VERSION ""

NS_ :

BS_:

BU_:

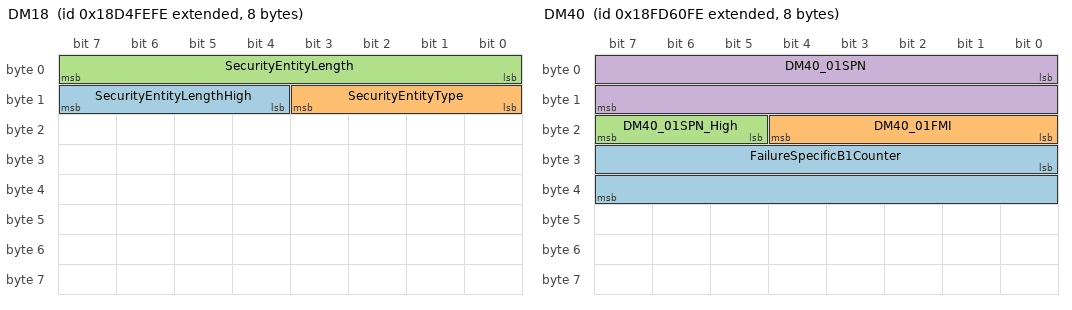
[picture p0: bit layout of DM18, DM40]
BO_ 2564095742 DM18: 8 Vector__XXX
 SG_ SecurityEntityLengthHigh : 12|4@1+ (1,0) [0|255] "Byte" Vector__XXX
 SG_ SecurityEntityType : 8|4@1+ (1,0) [0|15] "" Vector__XXX
 SG_ SecurityEntityLength : 0|8@1+ (1,0) [0|1785] "Byte" Vector__XXX

BO_ 2566742270 DM40: 8 Vector__XXX
 SG_ FailureSpecificB1Counter : 24|16@1+ (0.1,0) [0|6425.5] "hr" Vector__XXX
 SG_ DM40_01FMI : 16|5@1+ (1,0) [0|0] "" Vector__XXX
 SG_ DM40_01SPN_High : 21|3@1+ (65536,0) [0|0] "" Vector__XXX
 SG_ DM40_01SPN : 0|16@1+ (1,0) [0|65536] "" Vector__XXX

BO_ 2566742526 DM39: 8 Vector__XXX
 SG_ SysGreatestB1Counter : 32|16@1+ (0.1,0) [0|6425.5] "hr" Vector__XXX
 SG_ SysCumulativeContinuousMITime : 0|32@1+ (0.05,0) [0|210554060.75] "hr" Vector__XXX

BO_ 2566742782 DM38: 8 Vector__XXX
 SG_ RegulationDescription : 0|8@1+ (1,0) [0|255] "" Vector__XXX

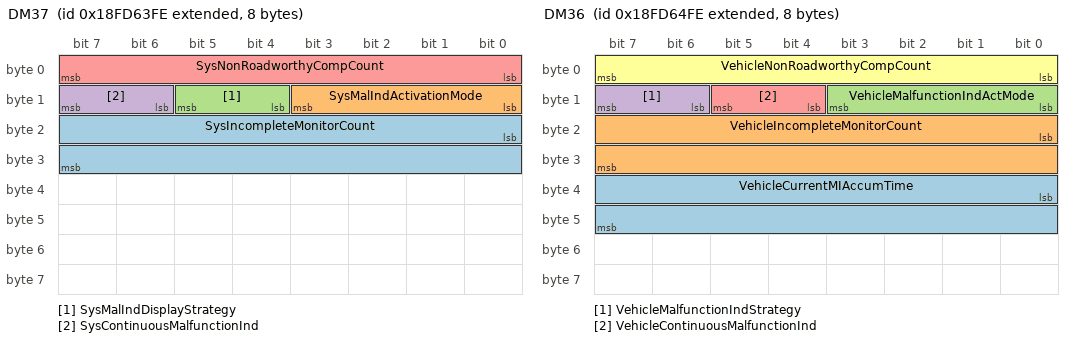
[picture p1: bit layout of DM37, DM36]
BO_ 2566743038 DM37: 8 Vector__XXX
 SG_ SysIncompleteMonitorCount : 16|16@1+ (1,0) [0|64512] "" Vector__XXX
 SG_ SysMalIndActivationMode : 8|4@1+ (1,0) [0|15] "" Vector__XXX
 SG_ SysMalIndDisplayStrategy : 12|2@1+ (1,0) [0|3] "" Vector__XXX
 SG_ SysContinuousMalfunctionInd : 14|2@1+ (1,0) [0|3] "" Vector__XXX
 SG_ SysNonRoadworthyCompCount : 0|8@1+ (1,0) [0|250] "" Vector__XXX

BO_ 2566743294 DM36: 8 Vector__XXX
 SG_ VehicleCurrentMIAccumTime : 32|16@1+ (1,0) [0|64255] "min" Vector__XXX
 SG_ VehicleIncompleteMonitorCount : 16|16@1+ (1,0) [0|64255] "" Vector__XXX
 SG_ VehicleMalfunctionIndActMode : 8|4@1+ (1,0) [0|15] "" Vector__XXX
 SG_ VehicleMalfunctionIndStrategy : 14|2@1+ (1,0) [0|3] "" Vector__XXX
 SG_ VehicleContinuousMalfunctionInd : 12|2@1+ (1,0) [0|3] "" Vector__XXX
 SG_ VehicleNonRoadworthyCompCount : 0|8@1+ (1,0) [0|250] "" Vector__XXX

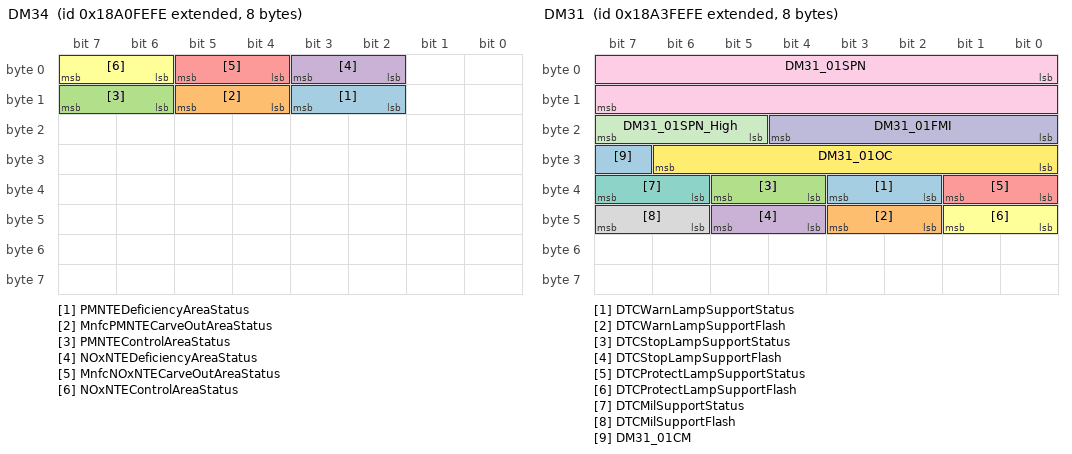
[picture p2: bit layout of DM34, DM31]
BO_ 2560687870 DM34: 8 Vector__XXX
 SG_ PMNTEDeficiencyAreaStatus : 10|2@1+ (1,0) [0|3] "" Vector__XXX
 SG_ MnfcPMNTECarveOutAreaStatus : 12|2@1+ (1,0) [0|3] "" Vector__XXX
 SG_ PMNTEControlAreaStatus : 14|2@1+ (1,0) [0|3] "" Vector__XXX
 SG_ NOxNTEDeficiencyAreaStatus : 2|2@1+ (1,0) [0|3] "" Vector__XXX
 SG_ MnfcNOxNTECarveOutAreaStatus : 4|2@1+ (1,0) [0|3] "" Vector__XXX
 SG_ NOxNTEControlAreaStatus : 6|2@1+ (1,0) [0|3] "" Vector__XXX

BO_ 2292317950 DM33: 9 Vector__XXX
 SG_ AECDEngineHours1Timer2 : 40|32@1+ (1,0) [0|4294967295] "min" Vector__XXX
 SG_ AECDEngineHours1Timer1 : 8|32@1+ (1,0) [0|4294967295] "min" Vector__XXX
 SG_ AECDNumber1 : 0|8@1+ (1,0) [0|250] "" Vector__XXX

BO_ 2560884478 DM31: 8 Vector__XXX
 SG_ DTCWarnLampSupportStatus : 34|2@1+ (1,0) [0|3] "" Vector__XXX
 SG_ DTCWarnLampSupportFlash : 42|2@1+ (1,0) [0|3] "" Vector__XXX
 SG_ DTCStopLampSupportStatus : 36|2@1+ (1,0) [0|3] "" Vector__XXX
 SG_ DTCStopLampSupportFlash : 44|2@1+ (1,0) [0|3] "" Vector__XXX
 SG_ DTCProtectLampSupportStatus : 32|2@1+ (1,0) [0|3] "" Vector__XXX
 SG_ DTCProtectLampSupportFlash : 40|2@1+ (1,0) [0|3] "" Vector__XXX
 SG_ DTCMilSupportStatus : 38|2@1+ (1,0) [0|3] "" Vector__XXX
 SG_ DTCMilSupportFlash : 46|2@1+ (1,0) [0|3] "" Vector__XXX
 SG_ DM31_01SPN : 0|16@1+ (1,0) [0|0] "" Vector__XXX
 SG_ DM31_01FMI : 16|5@1+ (1,0) [0|0] "" Vector__XXX
 SG_ DM31_01SPN_High : 21|3@1+ (65536,0) [0|0] "" Vector__XXX
 SG_ DM31_01OC : 24|7@1+ (1,0) [0|0] "" Vector__XXX
 SG_ DM31_01CM : 31|1@1+ (1,0) [0|0] "" Vector__XXX

BO_ 2560950014 DM30: 12 Vector__XXX
 SG_ TestLimitMinimum : 80|16@1+ (1,0) [0|64255] "" Vector__XXX
 SG_ TestLimitMaximum : 64|16@1+ (1,0) [0|64255] "" Vector__XXX
 SG_ TestValue : 48|16@1+ (1,0) [0|64255] "" Vector__XXX
 SG_ SlotId : 32|16@1+ (1,0) [0|64255] "" Vector__XXX
 SG_ TestIdentifier : 0|8@1+ (1,0) [0|255] "" Vector__XXX
 SG_ DM30_01FMI : 24|5@1+ (1,0) [0|0] "" Vector__XXX
 SG_ DM30_01SPN_High : 29|3@1+ (65536,0) [0|0] "" Vector__XXX
 SG_ DM30_01SPN : 8|16@1+ (1,0) [0|65536] "" Vector__XXX

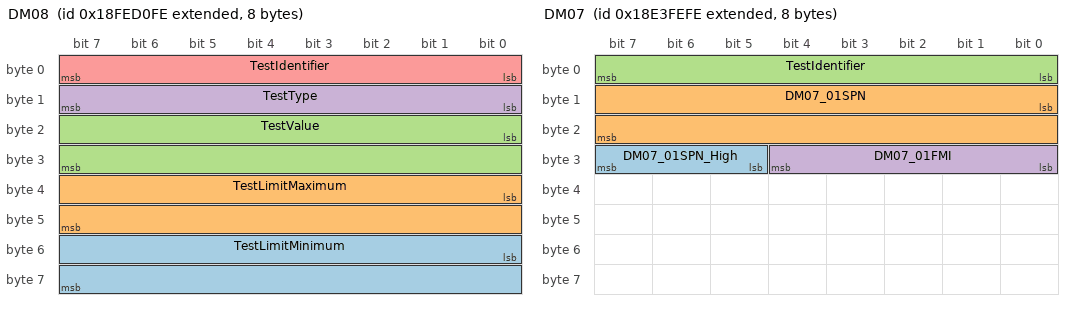
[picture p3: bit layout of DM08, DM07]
BO_ 2566836478 DM08: 8 Vector__XXX
 SG_ TestLimitMinimum : 48|16@1+ (1,0) [0|64255] "" Vector__XXX
 SG_ TestLimitMaximum : 32|16@1+ (1,0) [0|64255] "" Vector__XXX
 SG_ TestValue : 16|16@1+ (1,0) [0|64255] "" Vector__XXX
 SG_ TestType : 8|8@1+ (1,0) [1|64] "" Vector__XXX
 SG_ TestIdentifier : 0|8@1+ (1,0) [1|64] "" Vector__XXX

BO_ 2565078782 DM07: 8 Vector__XXX
 SG_ DM07_01SPN_High : 29|3@1+ (65536,0) [0|0] "" Vector__XXX
 SG_ DM07_01SPN : 8|16@1+ (1,0) [0|65536] "" Vector__XXX
 SG_ TestIdentifier : 0|8@1+ (1,0) [1|64] "" Vector__XXX
 SG_ DM07_01FMI : 24|5@1+ (1,0) [0|0] "" Vector__XXX

BO_ 2566836222 DM06: 78 Vector__XXX
 SG_ FlashRedStopLamp : 12|2@1+ (1,0) [0|3] "" Vector__XXX
 SG_ FlashProtectLamp : 8|2@1+ (1,0) [0|3] "" Vector__XXX
 SG_ FlashMalfuncIndicatorLamp : 14|2@1+ (1,0) [0|3] "" Vector__XXX
 SG_ FlashAmberWarningLamp : 10|2@1+ (1,0) [0|3] "" Vector__XXX
 SG_ MalfunctionIndicatorLampStatus : 6|2@1+ (1,0) [0|3] "" Vector__XXX
 SG_ RedStopLampStatus : 4|2@1+ (1,0) [0|3] "" Vector__XXX
 SG_ AmberWarningLampStatus : 2|2@1+ (1,0) [0|3] "" Vector__XXX
 SG_ ProtectLampStatus : 0|2@1+ (1,0) [0|3] "" Vector__XXX
 SG_ DM06_01OC : 40|7@1+ (1,0) [0|0] "" Vector__XXX
 SG_ DM06_01FMI : 32|5@1+ (1,0) [0|0] "" Vector__XXX
 SG_ DM06_01SPN : 16|16@1+ (1,0) [0|0] "" Vector__XXX
 SG_ DM06_02OC : 72|7@1+ (1,0) [0|0] "" Vector__XXX
 SG_ DM06_02FMI : 64|5@1+ (1,0) [0|0] "" Vector__XXX
 SG_ DM06_02SPN : 48|16@1+ (1,0) [0|0] "" Vector__XXX
 SG_ DM06_03OC : 104|7@1+ (1,0) [0|0] "" Vector__XXX
 SG_ DM06_03FMI : 96|5@1+ (1,0) [0|0] "" Vector__XXX
 SG_ DM06_03SPN : 80|16@1+ (1,0) [0|0] "" Vector__XXX
 SG_ DM06_04OC : 136|7@1+ (1,0) [0|0] "" Vector__XXX
 SG_ DM06_04FMI : 128|5@1+ (1,0) [0|0] "" Vector__XXX
 SG_ DM06_04SPN : 112|16@1+ (1,0) [0|0] "" Vector__XXX
 SG_ DM06_05OC : 168|7@1+ (1,0) [0|0] "" Vector__XXX
 SG_ DM06_05FMI : 160|5@1+ (1,0) [0|0] "" Vector__XXX
 SG_ DM06_05SPN : 144|16@1+ (1,0) [0|0] "" Vector__XXX
 SG_ DM06_06OC : 200|7@1+ (1,0) [0|0] "" Vector__XXX
 SG_ DM06_06FMI : 192|5@1+ (1,0) [0|0] "" Vector__XXX
 SG_ DM06_06SPN : 176|16@1+ (1,0) [0|0] "" Vector__XXX
 SG_ DM06_07OC : 232|7@1+ (1,0) [0|0] "" Vector__XXX
 SG_ DM06_07FMI : 224|5@1+ (1,0) [0|0] "" Vector__XXX
 SG_ DM06_07SPN : 208|16@1+ (1,0) [0|0] "" Vector__XXX
 SG_ DM06_08OC : 264|7@1+ (1,0) [0|0] "" Vector__XXX
 SG_ DM06_08FMI : 256|5@1+ (1,0) [0|0] "" Vector__XXX
 SG_ DM06_08SPN : 240|16@1+ (1,0) [0|0] "" Vector__XXX
 SG_ DM06_09OC : 296|7@1+ (1,0) [0|0] "" Vector__XXX
 SG_ DM06_09FMI : 288|5@1+ (1,0) [0|0] "" Vector__XXX
 SG_ DM06_09SPN : 272|16@1+ (1,0) [0|0] "" Vector__XXX
 SG_ DM06_10OC : 328|7@1+ (1,0) [0|0] "" Vector__XXX
 SG_ DM06_10FMI : 320|5@1+ (1,0) [0|0] "" Vector__XXX
 SG_ DM06_10SPN : 304|16@1+ (1,0) [0|0] "" Vector__XXX
 SG_ DM06_11OC : 360|7@1+ (1,0) [0|0] "" Vector__XXX
 SG_ DM06_11FMI : 352|5@1+ (1,0) [0|0] "" Vector__XXX
 SG_ DM06_11SPN : 336|16@1+ (1,0) [0|0] "" Vector__XXX
 SG_ DM06_12OC : 392|7@1+ (1,0) [0|0] "" Vector__XXX
 SG_ DM06_12FMI : 384|5@1+ (1,0) [0|0] "" Vector__XXX
 SG_ DM06_12SPN : 368|16@1+ (1,0) [0|0] "" Vector__XXX
 SG_ DM06_13OC : 424|7@1+ (1,0) [0|0] "" Vector__XXX
 SG_ DM06_13FMI : 416|5@1+ (1,0) [0|0] "" Vector__XXX
 SG_ DM06_13SPN : 400|16@1+ (1,0) [0|0] "" Vector__XXX
 SG_ DM06_14OC : 456|7@1+ (1,0) [0|0] "" Vector__XXX
 SG_ DM06_14FMI : 448|5@1+ (1,0) [0|0] "" Vector__XXX
 SG_ DM06_14SPN : 432|16@1+ (1,0) [0|0] "" Vector__XXX
 SG_ DM06_15OC : 488|7@1+ (1,0) [0|0] "" Vector__XXX
 SG_ DM06_15FMI : 480|5@1+ (1,0) [0|0] "" Vector__XXX
 SG_ DM06_15SPN : 464|16@1+ (1,0) [0|0] "" Vector__XXX
 SG_ DM06_16OC : 520|7@1+ (1,0) [0|0] "" Vector__XXX
 SG_ DM06_16FMI : 512|5@1+ (1,0) [0|0] "" Vector__XXX
 SG_ DM06_16SPN : 496|16@1+ (1,0) [0|0] "" Vector__XXX
 SG_ DM06_17OC : 552|7@1+ (1,0) [0|0] "" Vector__XXX
 SG_ DM06_17FMI : 544|5@1+ (1,0) [0|0] "" Vector__XXX
 SG_ DM06_17SPN : 528|16@1+ (1,0) [0|0] "" Vector__XXX
 SG_ DM06_18OC : 584|7@1+ (1,0) [0|0] "" Vector__XXX
 SG_ DM06_18FMI : 576|5@1+ (1,0) [0|0] "" Vector__XXX
 SG_ DM06_18SPN : 560|16@1+ (1,0) [0|0] "" Vector__XXX
 SG_ DM06_19OC : 616|7@1+ (1,0) [0|0] "" Vector__XXX
 SG_ DM06_19FMI : 608|5@1+ (1,0) [0|0] "" Vector__XXX
 SG_ DM06_19SPN : 592|16@1+ (1,0) [0|0] "" Vector__XXX
 SG_ DM06_19SPN_High : 613|3@1+ (65536,0) [0|0] "" Vector__XXX
 SG_ DM06_18SPN_High : 581|3@1+ (65536,0) [0|0] "" Vector__XXX
 SG_ DM06_17SPN_High : 549|3@1+ (65536,0) [0|0] "" Vector__XXX
 SG_ DM06_16SPN_High : 517|3@1+ (65536,0) [0|0] "" Vector__XXX
 SG_ DM06_15SPN_High : 485|3@1+ (65536,0) [0|0] "" Vector__XXX
 SG_ DM06_14SPN_High : 453|3@1+ (65536,0) [0|0] "" Vector__XXX
 SG_ DM06_13SPN_High : 421|3@1+ (65536,0) [0|0] "" Vector__XXX
 SG_ DM06_12SPN_High : 389|3@1+ (65536,0) [0|0] "" Vector__XXX
 SG_ DM06_11SPN_High : 357|3@1+ (65536,0) [0|0] "" Vector__XXX
 SG_ DM06_10SPN_High : 325|3@1+ (65536,0) [0|0] "" Vector__XXX
 SG_ DM06_09SPN_High : 293|3@1+ (65536,0) [0|0] "" Vector__XXX
 SG_ DM06_08SPN_High : 261|3@1+ (65536,0) [0|0] "" Vector__XXX
 SG_ DM06_07SPN_High : 229|3@1+ (65536,0) [0|0] "" Vector__XXX
 SG_ DM06_06SPN_High : 197|3@1+ (65536,0) [0|0] "" Vector__XXX
 SG_ DM06_05SPN_High : 165|3@1+ (65536,0) [0|0] "" Vector__XXX
 SG_ DM06_04SPN_High : 133|3@1+ (65536,0) [0|0] "" Vector__XXX
 SG_ DM06_03SPN_High : 101|3@1+ (65536,0) [0|0] "" Vector__XXX
 SG_ DM06_02SPN_High : 69|3@1+ (65536,0) [0|0] "" Vector__XXX
 SG_ DM06_01SPN_High : 37|3@1+ (65536,0) [0|0] "" Vector__XXX
 SG_ DM06_01CM : 47|1@1+ (1,0) [0|0] "" Vector__XXX
 SG_ DM06_02CM : 79|1@1+ (1,0) [0|0] "" Vector__XXX
 SG_ DM06_03CM : 111|1@1+ (1,0) [0|0] "" Vector__XXX
 SG_ DM06_04CM : 143|1@1+ (1,0) [0|0] "" Vector__XXX
 SG_ DM06_05CM : 175|1@1+ (1,0) [0|0] "" Vector__XXX
 SG_ DM06_06CM : 207|1@1+ (1,0) [0|0] "" Vector__XXX
 SG_ DM06_07CM : 239|1@1+ (1,0) [0|0] "" Vector__XXX
 SG_ DM06_08CM : 271|1@1+ (1,0) [0|0] "" Vector__XXX
 SG_ DM06_09CM : 303|1@1+ (1,0) [0|0] "" Vector__XXX
 SG_ DM06_10CM : 335|1@1+ (1,0) [0|0] "" Vector__XXX
 SG_ DM06_11CM : 367|1@1+ (1,0) [0|0] "" Vector__XXX
 SG_ DM06_12CM : 399|1@1+ (1,0) [0|0] "" Vector__XXX
 SG_ DM06_13CM : 431|1@1+ (1,0) [0|0] "" Vector__XXX
 SG_ DM06_14CM : 463|1@1+ (1,0) [0|0] "" Vector__XXX
 SG_ DM06_15CM : 495|1@1+ (1,0) [0|0] "" Vector__XXX
 SG_ DM06_16CM : 527|1@1+ (1,0) [0|0] "" Vector__XXX
 SG_ DM06_17CM : 559|1@1+ (1,0) [0|0] "" Vector__XXX
 SG_ DM06_18CM : 591|1@1+ (1,0) [0|0] "" Vector__XXX
 SG_ DM06_19CM : 623|1@1+ (1,0) [0|0] "" Vector__XXX

BO_ 2566835966 DM05: 8 Vector__XXX
 SG_ BoostPressureControlSystemStatus : 57|1@1- (1,0) [0|0] "" Vector__XXX
 SG_ DieselParticulateFilterStatus : 58|1@1- (1,0) [0|0] "" Vector__XXX
 SG_ NOxConvertingCatalystAdsorberSta : 59|1@1- (1,0) [0|0] "" Vector__XXX
 SG_ NMHCConvertingCatalystStatus : 60|1@1- (1,0) [0|0] "" Vector__XXX
 SG_ BoostPressureControlSystemSuppor : 41|1@1- (1,0) [0|0] "" Vector__XXX
 SG_ DieselParticulateFilterSupport : 42|1@1- (1,0) [0|0] "" Vector__XXX
 SG_ NOxConvertingCatalystAdsorberSup : 43|1@1- (1,0) [0|0] "" Vector__XXX
 SG_ NMHCConvertingCatalystSupport : 44|1@1- (1,0) [0|0] "" Vector__XXX
 SG_ MisfireMonitoringSupport : 24|1@1+ (1,0) [0|0] "" Vector__XXX
 SG_ OBDCompliance : 16|8@1+ (1,0) [0|240] "" Vector__XXX
 SG_ PreviouslyActiveTroubleCodeCount : 8|8@1+ (1,0) [0|240] "" Vector__XXX
 SG_ ActiveTroubleCodeCount : 0|8@1+ (1,0) [0|240] "" Vector__XXX
 SG_ SecondAirSystemMonStatus : 51|1@1+ (1,0) [0|1] "" Vector__XXX
 SG_ EvaporativeSystemMonStatus : 50|1@1+ (1,0) [0|1] "" Vector__XXX
 SG_ ACSystemRefrigerantMonStatus : 52|1@1+ (1,0) [0|1] "" Vector__XXX
 SG_ OxygenSensorHeaterMonStatus : 54|1@1+ (1,0) [0|1] "" Vector__XXX
 SG_ OxygenSensorMonStatus : 53|1@1+ (1,0) [0|1] "" Vector__XXX
 SG_ EGRSystemMonitoringStatus : 55|1@1+ (1,0) [0|1] "" Vector__XXX
 SG_ CatalystMonStatus : 48|1@1+ (1,0) [0|1] "" Vector__XXX
 SG_ ColdStartAidSystemMonStatus : 56|1@1+ (1,0) [0|1] "" Vector__XXX
 SG_ HeatedCatalystMonStatus : 49|1@1+ (1,0) [0|0] "" Vector__XXX
 SG_ CatalystMonSupp : 32|1@1+ (1,0) [0|1] "" Vector__XXX
 SG_ ColdStartAidSystemMonSupp : 40|1@1+ (1,0) [0|1] "" Vector__XXX
 SG_ HeatedCatalystMonSupp : 33|1@1+ (1,0) [0|0] "" Vector__XXX
 SG_ EvaporativeSystemMonSupp : 34|1@1+ (1,0) [0|1] "" Vector__XXX
 SG_ SecondAirSystemMonSupp : 35|1@1+ (1,0) [0|1] "" Vector__XXX
 SG_ ACSystemRefrigerantMonSupp : 36|1@1+ (1,0) [0|1] "" Vector__XXX
 SG_ OxygenSensorMonSupp : 37|1@1+ (1,0) [0|1] "" Vector__XXX
 SG_ OxygenSensorHeaterMonSupp : 38|1@1+ (1,0) [0|1] "" Vector__XXX
 SG_ EGRSystemMonitoringSupp : 39|1@1+ (1,0) [0|1] "" Vector__XXX
 SG_ MisfireMonitoringStatus : 28|1@1+ (1,0) [0|0] "" Vector__XXX
 SG_ ComprehensiveCompMonStatus : 30|1@1+ (1,0) [0|1] "" Vector__XXX
 SG_ FuelSystemMonitoringStatus : 29|1@1+ (1,0) [0|1] "" Vector__XXX
 SG_ ComprehensiveComponentMonSupp : 26|1@1+ (1,0) [0|0] "" Vector__XXX
 SG_ FuelSystemMonitoringSupport : 25|1@1+ (1,0) [0|1] "" Vector__XXX

BO_ 2566835710 DM04: 13 Vector__XXX
 SG_ EngIntakeManifold1Press : 48|8@1+ (2,0) [0|500] "kPa" Vector__XXX
 SG_ FreezeFrameLength : 0|8@1+ (1,0) [0|255] "Byte" Vector__XXX
 SG_ EngSpeed : 56|16@1+ (0.125,0) [0|8031.875] "rpm" Vector__XXX
 SG_ EngTorqueMode : 40|4@1+ (1,0) [0|15] "" Vector__XXX
 SG_ WheelBasedVehicleSpeed : 88|16@1+ (0.00390625,0) [0|250.996] "km/h" Vector__XXX
 SG_ EngPercentLoadAtCurrentSpeed : 72|8@1+ (1,0) [0|250] "%" Vector__XXX
 SG_ EngineCoolantTemperature : 80|8@1+ (1,-40) [-40|210] "deg C" Vector__XXX
 SG_ DM04_01SPN : 8|16@1+ (1,0) [0|0] "" Vector__XXX
 SG_ DM04_01FMI : 24|5@1+ (1,0) [0|0] "" Vector__XXX
 SG_ DM04_01SPN_High : 29|3@1+ (65536,0) [0|0] "" Vector__XXX
 SG_ DM04_01OC : 32|7@1+ (1,0) [0|0] "" Vector__XXX
 SG_ DM04_01CM : 39|1@1+ (1,0) [0|0] "" Vector__XXX

BO_ 2566835454 DM03: 0 Vector__XXX

BO_ 2566764542 DM25: 13 Vector__XXX
 SG_ ExpandedFreezeFrameLength : 0|8@1+ (1,0) [0|255] "Byte" Vector__XXX
 SG_ DM25_01SPN : 8|16@1+ (1,0) [0|0] "" Vector__XXX
 SG_ DM25_01FMI : 24|5@1+ (1,0) [0|0] "" Vector__XXX
 SG_ DM25_01SPN_High : 29|3@1+ (65536,0) [0|0] "" Vector__XXX
 SG_ DM25_01OC : 32|7@1+ (1,0) [0|0] "" Vector__XXX
 SG_ DM25_01CM : 39|1@1+ (1,0) [0|0] "" Vector__XXX

BO_ 2566764286 DM24: 12 Vector__XXX
 SG_ SPNSupported1High : 21|3@1+ (65536,0) [0|0] "" Vector__XXX
 SG_ SPNSupportTypeSTR3 : 82|1@1+ (1,0) [0|1] "" Vector__XXX
 SG_ SPNSupportTypeSTR2 : 81|1@1+ (1,0) [0|1] "" Vector__XXX
 SG_ SPNSupportTypeEFF3 : 80|1@1+ (1,0) [0|1] "" Vector__XXX
 SG_ SPNSupportTypeEFF2 : 48|1@1+ (1,0) [0|1] "" Vector__XXX
 SG_ SPNSupportTypeDS3 : 50|1@1+ (1,0) [0|1] "" Vector__XXX
 SG_ SPNSupportTypeDS2 : 49|1@1+ (1,0) [0|1] "" Vector__XXX
 SG_ SPNSupported3High : 85|3@1+ (65536,0) [0|0] "" Vector__XXX
 SG_ SPNSupported2High : 53|3@1+ (65536,0) [0|0] "" Vector__XXX
 SG_ SPNSupported3 : 64|16@1+ (1,0) [0|65535] "" Vector__XXX
 SG_ SPNSupported2 : 32|16@1+ (1,0) [0|65535] "" Vector__XXX
 SG_ SPNDataLength3 : 88|8@1+ (1,0) [0|240] "" Vector__XXX
 SG_ SPNSupportTypeSTR1 : 18|1@1+ (1,0) [0|1] "" Vector__XXX
 SG_ SPNSupportTypeDS1 : 17|1@1+ (1,0) [0|1] "" Vector__XXX
 SG_ SPNSupportTypeEFF1 : 16|1@1+ (1,0) [0|1] "" Vector__XXX
 SG_ SPNDataLength2 : 56|8@1+ (1,0) [0|240] "" Vector__XXX
 SG_ SPNDataLength1 : 24|8@1+ (1,0) [0|240] "" Vector__XXX
 SG_ SPNSupported1 : 0|16@1+ (1,0) [0|65535] "" Vector__XXX

BO_ 2566764030 DM23: 78 Vector__XXX
 SG_ FlashRedStopLamp : 12|2@1+ (1,0) [0|3] "" Vector__XXX
 SG_ FlashProtectLamp : 8|2@1+ (1,0) [0|3] "" Vector__XXX
 SG_ FlashMalfuncIndicatorLamp : 14|2@1+ (1,0) [0|3] "" Vector__XXX
 SG_ FlashAmberWarningLamp : 10|2@1+ (1,0) [0|3] "" Vector__XXX
 SG_ MalfunctionIndicatorLampStatus : 6|2@1+ (1,0) [0|3] "" Vector__XXX
 SG_ RedStopLampStatus : 4|2@1+ (1,0) [0|3] "" Vector__XXX
 SG_ AmberWarningLampStatus : 2|2@1+ (1,0) [0|3] "" Vector__XXX
 SG_ ProtectLampStatus : 0|2@1+ (1,0) [0|3] "" Vector__XXX
 SG_ DM23_01OC : 40|7@1+ (1,0) [0|0] "" Vector__XXX
 SG_ DM23_01FMI : 32|5@1+ (1,0) [0|0] "" Vector__XXX
 SG_ DM23_01SPN : 16|16@1+ (1,0) [0|0] "" Vector__XXX
 SG_ DM23_02OC : 72|7@1+ (1,0) [0|0] "" Vector__XXX
 SG_ DM23_02FMI : 64|5@1+ (1,0) [0|0] "" Vector__XXX
 SG_ DM23_02SPN : 48|16@1+ (1,0) [0|0] "" Vector__XXX
 SG_ DM23_03OC : 104|7@1+ (1,0) [0|0] "" Vector__XXX
 SG_ DM23_03FMI : 96|5@1+ (1,0) [0|0] "" Vector__XXX
 SG_ DM23_03SPN : 80|16@1+ (1,0) [0|0] "" Vector__XXX
 SG_ DM23_04OC : 136|7@1+ (1,0) [0|0] "" Vector__XXX
 SG_ DM23_04FMI : 128|5@1+ (1,0) [0|0] "" Vector__XXX
 SG_ DM23_04SPN : 112|16@1+ (1,0) [0|0] "" Vector__XXX
 SG_ DM23_05OC : 168|7@1+ (1,0) [0|0] "" Vector__XXX
 SG_ DM23_05FMI : 160|5@1+ (1,0) [0|0] "" Vector__XXX
 SG_ DM23_05SPN : 144|16@1+ (1,0) [0|0] "" Vector__XXX
 SG_ DM23_06OC : 200|7@1+ (1,0) [0|0] "" Vector__XXX
 SG_ DM23_06FMI : 192|5@1+ (1,0) [0|0] "" Vector__XXX
 SG_ DM23_06SPN : 176|16@1+ (1,0) [0|0] "" Vector__XXX
 SG_ DM23_07OC : 232|7@1+ (1,0) [0|0] "" Vector__XXX
 SG_ DM23_07FMI : 224|5@1+ (1,0) [0|0] "" Vector__XXX
 SG_ DM23_07SPN : 208|16@1+ (1,0) [0|0] "" Vector__XXX
 SG_ DM23_08OC : 264|7@1+ (1,0) [0|0] "" Vector__XXX
 SG_ DM23_08FMI : 256|5@1+ (1,0) [0|0] "" Vector__XXX
 SG_ DM23_08SPN : 240|16@1+ (1,0) [0|0] "" Vector__XXX
 SG_ DM23_09OC : 296|7@1+ (1,0) [0|0] "" Vector__XXX
 SG_ DM23_09FMI : 288|5@1+ (1,0) [0|0] "" Vector__XXX
 SG_ DM23_09SPN : 272|16@1+ (1,0) [0|0] "" Vector__XXX
 SG_ DM23_10OC : 328|7@1+ (1,0) [0|0] "" Vector__XXX
 SG_ DM23_10FMI : 320|5@1+ (1,0) [0|0] "" Vector__XXX
 SG_ DM23_10SPN : 304|16@1+ (1,0) [0|0] "" Vector__XXX
 SG_ DM23_11OC : 360|7@1+ (1,0) [0|0] "" Vector__XXX
 SG_ DM23_11FMI : 352|5@1+ (1,0) [0|0] "" Vector__XXX
 SG_ DM23_11SPN : 336|16@1+ (1,0) [0|0] "" Vector__XXX
 SG_ DM23_12OC : 392|7@1+ (1,0) [0|0] "" Vector__XXX
 SG_ DM23_12FMI : 384|5@1+ (1,0) [0|0] "" Vector__XXX
 SG_ DM23_12SPN : 368|16@1+ (1,0) [0|0] "" Vector__XXX
 SG_ DM23_13OC : 424|7@1+ (1,0) [0|0] "" Vector__XXX
 SG_ DM23_13FMI : 416|5@1+ (1,0) [0|0] "" Vector__XXX
 SG_ DM23_13SPN : 400|16@1+ (1,0) [0|0] "" Vector__XXX
 SG_ DM23_14OC : 456|7@1+ (1,0) [0|0] "" Vector__XXX
 SG_ DM23_14FMI : 448|5@1+ (1,0) [0|0] "" Vector__XXX
 SG_ DM23_14SPN : 432|16@1+ (1,0) [0|0] "" Vector__XXX
 SG_ DM23_15OC : 488|7@1+ (1,0) [0|0] "" Vector__XXX
 SG_ DM23_15FMI : 480|5@1+ (1,0) [0|0] "" Vector__XXX
 SG_ DM23_15SPN : 464|16@1+ (1,0) [0|0] "" Vector__XXX
 SG_ DM23_16OC : 520|7@1+ (1,0) [0|0] "" Vector__XXX
 SG_ DM23_16FMI : 512|5@1+ (1,0) [0|0] "" Vector__XXX
 SG_ DM23_16SPN : 496|16@1+ (1,0) [0|0] "" Vector__XXX
 SG_ DM23_17OC : 552|7@1+ (1,0) [0|0] "" Vector__XXX
 SG_ DM23_17FMI : 544|5@1+ (1,0) [0|0] "" Vector__XXX
 SG_ DM23_17SPN : 528|16@1+ (1,0) [0|0] "" Vector__XXX
 SG_ DM23_18OC : 584|7@1+ (1,0) [0|0] "" Vector__XXX
 SG_ DM23_18FMI : 576|5@1+ (1,0) [0|0] "" Vector__XXX
 SG_ DM23_18SPN : 560|16@1+ (1,0) [0|0] "" Vector__XXX
 SG_ DM23_19OC : 616|7@1+ (1,0) [0|0] "" Vector__XXX
 SG_ DM23_19FMI : 608|5@1+ (1,0) [0|0] "" Vector__XXX
 SG_ DM23_19SPN : 592|16@1+ (1,0) [0|0] "" Vector__XXX
 SG_ DM23_19SPN_High : 613|3@1+ (65536,0) [0|0] "" Vector__XXX
 SG_ DM23_18SPN_High : 581|3@1+ (65536,0) [0|0] "" Vector__XXX
 SG_ DM23_17SPN_High : 549|3@1+ (65536,0) [0|0] "" Vector__XXX
 SG_ DM23_16SPN_High : 517|3@1+ (65536,0) [0|0] "" Vector__XXX
 SG_ DM23_15SPN_High : 485|3@1+ (65536,0) [0|0] "" Vector__XXX
 SG_ DM23_14SPN_High : 453|3@1+ (65536,0) [0|0] "" Vector__XXX
 SG_ DM23_13SPN_High : 421|3@1+ (65536,0) [0|0] "" Vector__XXX
 SG_ DM23_12SPN_High : 389|3@1+ (65536,0) [0|0] "" Vector__XXX
 SG_ DM23_11SPN_High : 357|3@1+ (65536,0) [0|0] "" Vector__XXX
 SG_ DM23_10SPN_High : 325|3@1+ (65536,0) [0|0] "" Vector__XXX
 SG_ DM23_09SPN_High : 293|3@1+ (65536,0) [0|0] "" Vector__XXX
 SG_ DM23_08SPN_High : 261|3@1+ (65536,0) [0|0] "" Vector__XXX
 SG_ DM23_07SPN_High : 229|3@1+ (65536,0) [0|0] "" Vector__XXX
 SG_ DM23_06SPN_High : 197|3@1+ (65536,0) [0|0] "" Vector__XXX
 SG_ DM23_05SPN_High : 165|3@1+ (65536,0) [0|0] "" Vector__XXX
 SG_ DM23_04SPN_High : 133|3@1+ (65536,0) [0|0] "" Vector__XXX
 SG_ DM23_03SPN_High : 101|3@1+ (65536,0) [0|0] "" Vector__XXX
 SG_ DM23_02SPN_High : 69|3@1+ (65536,0) [0|0] "" Vector__XXX
 SG_ DM23_01SPN_High : 37|3@1+ (65536,0) [0|0] "" Vector__XXX
 SG_ DM23_01CM : 47|1@1+ (1,0) [0|0] "" Vector__XXX
 SG_ DM23_02CM : 79|1@1+ (1,0) [0|0] "" Vector__XXX
 SG_ DM23_03CM : 111|1@1+ (1,0) [0|0] "" Vector__XXX
 SG_ DM23_04CM : 143|1@1+ (1,0) [0|0] "" Vector__XXX
 SG_ DM23_05CM : 175|1@1+ (1,0) [0|0] "" Vector__XXX
 SG_ DM23_06CM : 207|1@1+ (1,0) [0|0] "" Vector__XXX
 SG_ DM23_07CM : 239|1@1+ (1,0) [0|0] "" Vector__XXX
 SG_ DM23_08CM : 271|1@1+ (1,0) [0|0] "" Vector__XXX
 SG_ DM23_09CM : 303|1@1+ (1,0) [0|0] "" Vector__XXX
 SG_ DM23_10CM : 335|1@1+ (1,0) [0|0] "" Vector__XXX
 SG_ DM23_11CM : 367|1@1+ (1,0) [0|0] "" Vector__XXX
 SG_ DM23_12CM : 399|1@1+ (1,0) [0|0] "" Vector__XXX
 SG_ DM23_13CM : 431|1@1+ (1,0) [0|0] "" Vector__XXX
 SG_ DM23_14CM : 463|1@1+ (1,0) [0|0] "" Vector__XXX
 SG_ DM23_15CM : 495|1@1+ (1,0) [0|0] "" Vector__XXX
 SG_ DM23_16CM : 527|1@1+ (1,0) [0|0] "" Vector__XXX
 SG_ DM23_17CM : 559|1@1+ (1,0) [0|0] "" Vector__XXX
 SG_ DM23_18CM : 591|1@1+ (1,0) [0|0] "" Vector__XXX
 SG_ DM23_19CM : 623|1@1+ (1,0) [0|0] "" Vector__XXX

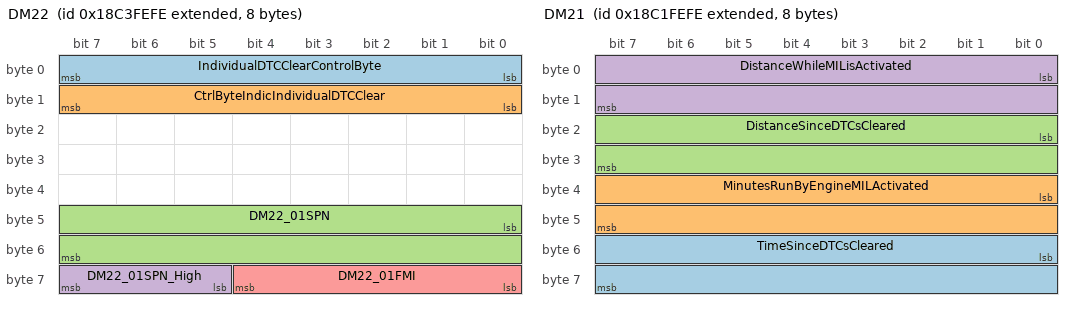
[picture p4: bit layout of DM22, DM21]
BO_ 2562981630 DM22: 8 Vector__XXX
 SG_ IndividualDTCClearControlByte : 0|8@1+ (1,0) [0|255] "" Vector__XXX
 SG_ CtrlByteIndicIndividualDTCClear : 8|8@1+ (1,0) [0|255] "" Vector__XXX
 SG_ DM22_01SPN : 40|16@1+ (1,0) [0|65536] "" Vector__XXX
 SG_ DM22_01SPN_High : 61|3@1+ (65536,0) [0|0] "" Vector__XXX
 SG_ DM22_01FMI : 56|5@1+ (1,0) [0|0] "" Vector__XXX

BO_ 2562850558 DM21: 8 Vector__XXX
 SG_ TimeSinceDTCsCleared : 48|16@1+ (1,0) [0|64255] "mins" Vector__XXX
 SG_ MinutesRunByEngineMILActivated : 32|16@1+ (1,0) [0|64255] "mins" Vector__XXX
 SG_ DistanceSinceDTCsCleared : 16|16@1+ (1,0) [0|64255] "km" Vector__XXX
 SG_ DistanceWhileMILisActivated : 0|16@1+ (1,0) [0|64255] "km" Vector__XXX

BO_ 2562916094 DM20: 11 Vector__XXX
 SG_ ApplSysMonitorDenominator : 72|16@1+ (1,0) [0|65535] "" Vector__XXX
 SG_ ApplSysMonitorNumerator : 56|16@1+ (1,0) [0|65535] "" Vector__XXX
 SG_ SPNofApplSysMonitor : 32|24@1+ (1,0) [0|524287] "" Vector__XXX
 SG_ OBDMonitoringCondEncountered : 16|16@1+ (1,0) [0|65535] "" Vector__XXX
 SG_ IgnitionCycleCounter : 0|16@1+ (1,0) [0|65535] "" Vector__XXX

BO_ 2566835198 DM02: 78 Vector__XXX
 SG_ MalfunctionIndicatorLampStatus : 6|2@1+ (1,0) [0|3] "" Vector__XXX
 SG_ RedStopLampStatus : 4|2@1+ (1,0) [0|3] "" Vector__XXX
 SG_ AmberWarningLampStatus : 2|2@1+ (1,0) [0|3] "" Vector__XXX
 SG_ ProtectLampStatus : 0|2@1+ (1,0) [0|3] "" Vector__XXX
 SG_ FlashRedStopLamp : 12|2@1+ (1,0) [0|3] "" Vector__XXX
 SG_ FlashProtectLamp : 8|2@1+ (1,0) [0|3] "" Vector__XXX
 SG_ FlashMalfuncIndicatorLamp : 14|2@1+ (1,0) [0|3] "" Vector__XXX
 SG_ FlashAmberWarningLamp : 10|2@1+ (1,0) [0|3] "" Vector__XXX
 SG_ DM02_01OC : 40|7@1+ (1,0) [0|0] "" Vector__XXX
 SG_ DM02_01FMI : 32|5@1+ (1,0) [0|0] "" Vector__XXX
 SG_ DM02_01SPN : 16|16@1+ (1,0) [0|0] "" Vector__XXX
 SG_ DM02_02OC : 72|7@1+ (1,0) [0|0] "" Vector__XXX
 SG_ DM02_02FMI : 64|5@1+ (1,0) [0|0] "" Vector__XXX
 SG_ DM02_02SPN : 48|16@1+ (1,0) [0|0] "" Vector__XXX
 SG_ DM02_03OC : 104|7@1+ (1,0) [0|0] "" Vector__XXX
 SG_ DM02_03FMI : 96|5@1+ (1,0) [0|0] "" Vector__XXX
 SG_ DM02_03SPN : 80|16@1+ (1,0) [0|0] "" Vector__XXX
 SG_ DM02_04OC : 136|7@1+ (1,0) [0|0] "" Vector__XXX
 SG_ DM02_04FMI : 128|5@1+ (1,0) [0|0] "" Vector__XXX
 SG_ DM02_04SPN : 112|16@1+ (1,0) [0|0] "" Vector__XXX
 SG_ DM02_05OC : 168|7@1+ (1,0) [0|0] "" Vector__XXX
 SG_ DM02_05FMI : 160|5@1+ (1,0) [0|0] "" Vector__XXX
 SG_ DM02_05SPN : 144|16@1+ (1,0) [0|0] "" Vector__XXX
 SG_ DM02_06OC : 200|7@1+ (1,0) [0|0] "" Vector__XXX
 SG_ DM02_06FMI : 192|5@1+ (1,0) [0|0] "" Vector__XXX
 SG_ DM02_06SPN : 176|16@1+ (1,0) [0|0] "" Vector__XXX
 SG_ DM02_07OC : 232|7@1+ (1,0) [0|0] "" Vector__XXX
 SG_ DM02_07FMI : 224|5@1+ (1,0) [0|0] "" Vector__XXX
 SG_ DM02_07SPN : 208|16@1+ (1,0) [0|0] "" Vector__XXX
 SG_ DM02_08OC : 264|7@1+ (1,0) [0|0] "" Vector__XXX
 SG_ DM02_08FMI : 256|5@1+ (1,0) [0|0] "" Vector__XXX
 SG_ DM02_08SPN : 240|16@1+ (1,0) [0|0] "" Vector__XXX
 SG_ DM02_09OC : 296|7@1+ (1,0) [0|0] "" Vector__XXX
 SG_ DM02_09FMI : 288|5@1+ (1,0) [0|0] "" Vector__XXX
 SG_ DM02_09SPN : 272|16@1+ (1,0) [0|0] "" Vector__XXX
 SG_ DM02_10OC : 328|7@1+ (1,0) [0|0] "" Vector__XXX
 SG_ DM02_10FMI : 320|5@1+ (1,0) [0|0] "" Vector__XXX
 SG_ DM02_10SPN : 304|16@1+ (1,0) [0|0] "" Vector__XXX
 SG_ DM02_11OC : 360|7@1+ (1,0) [0|0] "" Vector__XXX
 SG_ DM02_11FMI : 352|5@1+ (1,0) [0|0] "" Vector__XXX
 SG_ DM02_11SPN : 336|16@1+ (1,0) [0|0] "" Vector__XXX
 SG_ DM02_12OC : 392|7@1+ (1,0) [0|0] "" Vector__XXX
 SG_ DM02_12FMI : 384|5@1+ (1,0) [0|0] "" Vector__XXX
 SG_ DM02_12SPN : 368|16@1+ (1,0) [0|0] "" Vector__XXX
 SG_ DM02_13OC : 424|7@1+ (1,0) [0|0] "" Vector__XXX
 SG_ DM02_13FMI : 416|5@1+ (1,0) [0|0] "" Vector__XXX
 SG_ DM02_13SPN : 400|16@1+ (1,0) [0|0] "" Vector__XXX
 SG_ DM02_14OC : 456|7@1+ (1,0) [0|0] "" Vector__XXX
 SG_ DM02_14FMI : 448|5@1+ (1,0) [0|0] "" Vector__XXX
 SG_ DM02_14SPN : 432|16@1+ (1,0) [0|0] "" Vector__XXX
 SG_ DM02_15OC : 488|7@1+ (1,0) [0|0] "" Vector__XXX
 SG_ DM02_15FMI : 480|5@1+ (1,0) [0|0] "" Vector__XXX
 SG_ DM02_15SPN : 464|16@1+ (1,0) [0|0] "" Vector__XXX
 SG_ DM02_16OC : 520|7@1+ (1,0) [0|0] "" Vector__XXX
 SG_ DM02_16FMI : 512|5@1+ (1,0) [0|0] "" Vector__XXX
 SG_ DM02_16SPN : 496|16@1+ (1,0) [0|0] "" Vector__XXX
 SG_ DM02_17OC : 552|7@1+ (1,0) [0|0] "" Vector__XXX
 SG_ DM02_17FMI : 544|5@1+ (1,0) [0|0] "" Vector__XXX
 SG_ DM02_17SPN : 528|16@1+ (1,0) [0|0] "" Vector__XXX
 SG_ DM02_18OC : 584|7@1+ (1,0) [0|0] "" Vector__XXX
 SG_ DM02_18FMI : 576|5@1+ (1,0) [0|0] "" Vector__XXX
 SG_ DM02_18SPN : 560|16@1+ (1,0) [0|0] "" Vector__XXX
 SG_ DM02_19OC : 616|7@1+ (1,0) [0|0] "" Vector__XXX
 SG_ DM02_19FMI : 608|5@1+ (1,0) [0|0] "" Vector__XXX
 SG_ DM02_19SPN : 592|16@1+ (1,0) [0|0] "" Vector__XXX
 SG_ DM02_19SPN_High : 613|3@1+ (65536,0) [0|0] "" Vector__XXX
 SG_ DM02_18SPN_High : 581|3@1+ (65536,0) [0|0] "" Vector__XXX
 SG_ DM02_17SPN_High : 549|3@1+ (65536,0) [0|0] "" Vector__XXX
 SG_ DM02_16SPN_High : 517|3@1+ (65536,0) [0|0] "" Vector__XXX
 SG_ DM02_15SPN_High : 485|3@1+ (65536,0) [0|0] "" Vector__XXX
 SG_ DM02_14SPN_High : 453|3@1+ (65536,0) [0|0] "" Vector__XXX
 SG_ DM02_13SPN_High : 421|3@1+ (65536,0) [0|0] "" Vector__XXX
 SG_ DM02_12SPN_High : 389|3@1+ (65536,0) [0|0] "" Vector__XXX
 SG_ DM02_11SPN_High : 357|3@1+ (65536,0) [0|0] "" Vector__XXX
 SG_ DM02_10SPN_High : 325|3@1+ (65536,0) [0|0] "" Vector__XXX
 SG_ DM02_09SPN_High : 293|3@1+ (65536,0) [0|0] "" Vector__XXX
 SG_ DM02_08SPN_High : 261|3@1+ (65536,0) [0|0] "" Vector__XXX
 SG_ DM02_07SPN_High : 229|3@1+ (65536,0) [0|0] "" Vector__XXX
 SG_ DM02_06SPN_High : 197|3@1+ (65536,0) [0|0] "" Vector__XXX
 SG_ DM02_05SPN_High : 165|3@1+ (65536,0) [0|0] "" Vector__XXX
 SG_ DM02_04SPN_High : 133|3@1+ (65536,0) [0|0] "" Vector__XXX
 SG_ DM02_03SPN_High : 101|3@1+ (65536,0) [0|0] "" Vector__XXX
 SG_ DM02_02SPN_High : 69|3@1+ (65536,0) [0|0] "" Vector__XXX
 SG_ DM02_01SPN_High : 37|3@1+ (65536,0) [0|0] "" Vector__XXX
 SG_ DM02_01CM : 47|1@1+ (1,0) [0|0] "" Vector__XXX
 SG_ DM02_02CM : 79|1@1+ (1,0) [0|0] "" Vector__XXX
 SG_ DM02_03CM : 111|1@1+ (1,0) [0|0] "" Vector__XXX
 SG_ DM02_04CM : 143|1@1+ (1,0) [0|0] "" Vector__XXX
 SG_ DM02_05CM : 175|1@1+ (1,0) [0|0] "" Vector__XXX
 SG_ DM02_06CM : 207|1@1+ (1,0) [0|0] "" Vector__XXX
 SG_ DM02_07CM : 239|1@1+ (1,0) [0|0] "" Vector__XXX
 SG_ DM02_08CM : 271|1@1+ (1,0) [0|0] "" Vector__XXX
 SG_ DM02_09CM : 303|1@1+ (1,0) [0|0] "" Vector__XXX
 SG_ DM02_10CM : 335|1@1+ (1,0) [0|0] "" Vector__XXX
 SG_ DM02_11CM : 367|1@1+ (1,0) [0|0] "" Vector__XXX
 SG_ DM02_12CM : 399|1@1+ (1,0) [0|0] "" Vector__XXX
 SG_ DM02_13CM : 431|1@1+ (1,0) [0|0] "" Vector__XXX
 SG_ DM02_14CM : 463|1@1+ (1,0) [0|0] "" Vector__XXX
 SG_ DM02_15CM : 495|1@1+ (1,0) [0|0] "" Vector__XXX
 SG_ DM02_16CM : 527|1@1+ (1,0) [0|0] "" Vector__XXX
 SG_ DM02_17CM : 559|1@1+ (1,0) [0|0] "" Vector__XXX
 SG_ DM02_18CM : 591|1@1+ (1,0) [0|0] "" Vector__XXX
 SG_ DM02_19CM : 623|1@1+ (1,0) [0|0] "" Vector__XXX

BO_ 2564030206 DM19: 20 Vector__XXX
 SG_ CalibrationID4 : 128|32@1+ (1,0) [0|4294967295] "" Vector__XXX
 SG_ CalibrationID3 : 96|32@1+ (1,0) [0|4294967295] "" Vector__XXX
 SG_ CalibrationID2 : 64|32@1+ (1,0) [0|4294967295] "" Vector__XXX
 SG_ CalibrationID1 : 32|32@1+ (1,0) [0|4294967295] "" Vector__XXX
 SG_ CalibrationVerificationNumber : 0|32@1+ (1,0) [0|4294967295] "" Vector__XXX

BO_ 2564226814 DM17: 1 Vector__XXX
 SG_ BootLoadData : 0|8@1- (1,0) [0|0] "" Vector__XXX

BO_ 2564292350 DM16: 2 Vector__XXX
 SG_ RawBinaryData : 8|8@1- (1,0) [0|0] "" Vector__XXX
 SG_ NumberOfOccurance : 0|8@1+ (1,0) [0|0] "" Vector__XXX

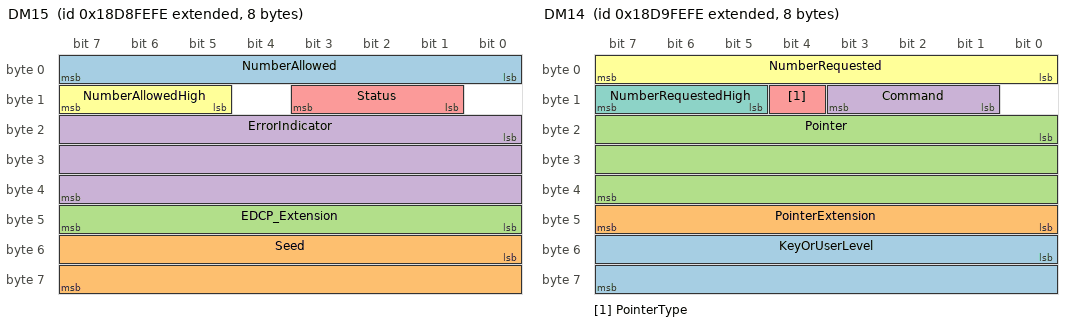
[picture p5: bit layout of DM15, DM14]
BO_ 2564357886 DM15: 8 Vector__XXX
 SG_ NumberAllowed : 0|8@1+ (1,0) [0|2047] "" Vector__XXX
 SG_ Seed : 48|16@1+ (1,0) [0|65535] "" Vector__XXX
 SG_ EDCP_Extension : 40|8@1+ (1,0) [0|255] "" Vector__XXX
 SG_ ErrorIndicator : 16|24@1+ (1,0) [0|16777215] "" Vector__XXX
 SG_ Status : 9|3@1+ (1,0) [0|7] "" Vector__XXX
 SG_ NumberAllowedHigh : 13|3@1+ (1,0) [0|7] "" Vector__XXX

BO_ 2564423422 DM14: 8 Vector__XXX
 SG_ KeyOrUserLevel : 48|16@1+ (1,0) [0|65535] "" Vector__XXX
 SG_ PointerExtension : 40|8@1+ (1,0) [0|255] "" Vector__XXX
 SG_ Pointer : 16|24@1+ (1,0) [0|16777215] "" Vector__XXX
 SG_ Command : 9|3@1+ (1,0) [0|7] "" Vector__XXX
 SG_ PointerType : 12|1@1+ (1,0) [0|1] "" Vector__XXX
 SG_ NumberRequested : 0|8@1+ (1,0) [0|2047] "" Vector__XXX
 SG_ NumberRequestedHigh : 13|3@1+ (1,0) [0|7] "" Vector__XXX

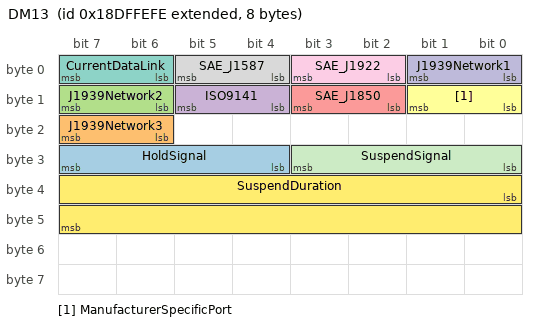
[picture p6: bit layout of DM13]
BO_ 2564816638 DM13: 8 Vector__XXX
 SG_ HoldSignal : 28|4@1+ (1,0) [0|15] "" Vector__XXX
 SG_ J1939Network3 : 22|2@1+ (1,0) [0|3] "" Vector__XXX
 SG_ J1939Network2 : 14|2@1+ (1,0) [0|3] "" Vector__XXX
 SG_ ISO9141 : 12|2@1+ (1,0) [0|3] "" Vector__XXX
 SG_ SAE_J1850 : 10|2@1+ (1,0) [0|3] "" Vector__XXX
 SG_ ManufacturerSpecificPort : 8|2@1+ (1,0) [0|3] "" Vector__XXX
 SG_ CurrentDataLink : 6|2@1+ (1,0) [0|3] "" Vector__XXX
 SG_ SAE_J1587 : 4|2@1+ (1,0) [0|3] "" Vector__XXX
 SG_ SAE_J1922 : 2|2@1+ (1,0) [0|3] "" Vector__XXX
 SG_ J1939Network1 : 0|2@1+ (1,0) [0|3] "" Vector__XXX
 SG_ SuspendSignal : 24|4@1+ (1,0) [0|15] "" Vector__XXX
 SG_ SuspendDuration : 32|16@1+ (1,0) [0|64255] "sec" Vector__XXX

BO_ 2566837502 DM12: 78 Vector__XXX
 SG_ FlashRedStopLamp : 12|2@1+ (1,0) [0|3] "" Vector__XXX
 SG_ FlashProtectLamp : 8|2@1+ (1,0) [0|3] "" Vector__XXX
 SG_ MalfunctionIndicatorLampStatus : 6|2@1+ (1,0) [0|3] "" Vector__XXX
 SG_ RedStopLampStatus : 4|2@1+ (1,0) [0|3] "" Vector__XXX
 SG_ AmberWarningLampStatus : 2|2@1+ (1,0) [0|3] "" Vector__XXX
 SG_ ProtectLampStatus : 0|2@1+ (1,0) [0|3] "" Vector__XXX
 SG_ FlashMalfuncIndicatorLamp : 14|2@1+ (1,0) [0|3] "" Vector__XXX
 SG_ FlashAmberWarningLamp : 10|2@1+ (1,0) [0|3] "" Vector__XXX
 SG_ DM12_01OC : 40|7@1+ (1,0) [0|0] "" Vector__XXX
 SG_ DM12_01FMI : 32|5@1+ (1,0) [0|0] "" Vector__XXX
 SG_ DM12_01SPN : 16|16@1+ (1,0) [0|0] "" Vector__XXX
 SG_ DM12_02OC : 72|7@1+ (1,0) [0|0] "" Vector__XXX
 SG_ DM12_02FMI : 64|5@1+ (1,0) [0|0] "" Vector__XXX
 SG_ DM12_02SPN : 48|16@1+ (1,0) [0|0] "" Vector__XXX
 SG_ DM12_03OC : 104|7@1+ (1,0) [0|0] "" Vector__XXX
 SG_ DM12_03FMI : 96|5@1+ (1,0) [0|0] "" Vector__XXX
 SG_ DM12_03SPN : 80|16@1+ (1,0) [0|0] "" Vector__XXX
 SG_ DM12_04OC : 136|7@1+ (1,0) [0|0] "" Vector__XXX
 SG_ DM12_04FMI : 128|5@1+ (1,0) [0|0] "" Vector__XXX
 SG_ DM12_04SPN : 112|16@1+ (1,0) [0|0] "" Vector__XXX
 SG_ DM12_05OC : 168|7@1+ (1,0) [0|0] "" Vector__XXX
 SG_ DM12_05FMI : 160|5@1+ (1,0) [0|0] "" Vector__XXX
 SG_ DM12_05SPN : 144|16@1+ (1,0) [0|0] "" Vector__XXX
 SG_ DM12_06OC : 200|7@1+ (1,0) [0|0] "" Vector__XXX
 SG_ DM12_06FMI : 192|5@1+ (1,0) [0|0] "" Vector__XXX
 SG_ DM12_06SPN : 176|16@1+ (1,0) [0|0] "" Vector__XXX
 SG_ DM12_07OC : 232|7@1+ (1,0) [0|0] "" Vector__XXX
 SG_ DM12_07FMI : 224|5@1+ (1,0) [0|0] "" Vector__XXX
 SG_ DM12_07SPN : 208|16@1+ (1,0) [0|0] "" Vector__XXX
 SG_ DM12_08OC : 264|7@1+ (1,0) [0|0] "" Vector__XXX
 SG_ DM12_08FMI : 256|5@1+ (1,0) [0|0] "" Vector__XXX
 SG_ DM12_08SPN : 240|16@1+ (1,0) [0|0] "" Vector__XXX
 SG_ DM12_09OC : 296|7@1+ (1,0) [0|0] "" Vector__XXX
 SG_ DM12_09FMI : 288|5@1+ (1,0) [0|0] "" Vector__XXX
 SG_ DM12_09SPN : 272|16@1+ (1,0) [0|0] "" Vector__XXX
 SG_ DM12_10OC : 328|7@1+ (1,0) [0|0] "" Vector__XXX
 SG_ DM12_10FMI : 320|5@1+ (1,0) [0|0] "" Vector__XXX
 SG_ DM12_10SPN : 304|16@1+ (1,0) [0|0] "" Vector__XXX
 SG_ DM12_11OC : 360|7@1+ (1,0) [0|0] "" Vector__XXX
 SG_ DM12_11FMI : 352|5@1+ (1,0) [0|0] "" Vector__XXX
 SG_ DM12_11SPN : 336|16@1+ (1,0) [0|0] "" Vector__XXX
 SG_ DM12_12OC : 392|7@1+ (1,0) [0|0] "" Vector__XXX
 SG_ DM12_12FMI : 384|5@1+ (1,0) [0|0] "" Vector__XXX
 SG_ DM12_12SPN : 368|16@1+ (1,0) [0|0] "" Vector__XXX
 SG_ DM12_13OC : 424|7@1+ (1,0) [0|0] "" Vector__XXX
 SG_ DM12_13FMI : 416|5@1+ (1,0) [0|0] "" Vector__XXX
 SG_ DM12_13SPN : 400|16@1+ (1,0) [0|0] "" Vector__XXX
 SG_ DM12_14OC : 456|7@1+ (1,0) [0|0] "" Vector__XXX
 SG_ DM12_14FMI : 448|5@1+ (1,0) [0|0] "" Vector__XXX
 SG_ DM12_14SPN : 432|16@1+ (1,0) [0|0] "" Vector__XXX
 SG_ DM12_15OC : 488|7@1+ (1,0) [0|0] "" Vector__XXX
 SG_ DM12_15FMI : 480|5@1+ (1,0) [0|0] "" Vector__XXX
 SG_ DM12_15SPN : 464|16@1+ (1,0) [0|0] "" Vector__XXX
 SG_ DM12_16OC : 520|7@1+ (1,0) [0|0] "" Vector__XXX
 SG_ DM12_16FMI : 512|5@1+ (1,0) [0|0] "" Vector__XXX
 SG_ DM12_16SPN : 496|16@1+ (1,0) [0|0] "" Vector__XXX
 SG_ DM12_17OC : 552|7@1+ (1,0) [0|0] "" Vector__XXX
 SG_ DM12_17FMI : 544|5@1+ (1,0) [0|0] "" Vector__XXX
 SG_ DM12_17SPN : 528|16@1+ (1,0) [0|0] "" Vector__XXX
 SG_ DM12_18OC : 584|7@1+ (1,0) [0|0] "" Vector__XXX
 SG_ DM12_18FMI : 576|5@1+ (1,0) [0|0] "" Vector__XXX
 SG_ DM12_18SPN : 560|16@1+ (1,0) [0|0] "" Vector__XXX
 SG_ DM12_19OC : 616|7@1+ (1,0) [0|0] "" Vector__XXX
 SG_ DM12_19FMI : 608|5@1+ (1,0) [0|0] "" Vector__XXX
 SG_ DM12_19SPN : 592|16@1+ (1,0) [0|0] "" Vector__XXX
 SG_ DM12_19SPN_High : 613|3@1+ (65536,0) [0|0] "" Vector__XXX
 SG_ DM12_18SPN_High : 581|3@1+ (65536,0) [0|0] "" Vector__XXX
 SG_ DM12_17SPN_High : 549|3@1+ (65536,0) [0|0] "" Vector__XXX
 SG_ DM12_16SPN_High : 517|3@1+ (65536,0) [0|0] "" Vector__XXX
 SG_ DM12_15SPN_High : 485|3@1+ (65536,0) [0|0] "" Vector__XXX
 SG_ DM12_14SPN_High : 453|3@1+ (65536,0) [0|0] "" Vector__XXX
 SG_ DM12_13SPN_High : 421|3@1+ (65536,0) [0|0] "" Vector__XXX
 SG_ DM12_12SPN_High : 389|3@1+ (65536,0) [0|0] "" Vector__XXX
 SG_ DM12_11SPN_High : 357|3@1+ (65536,0) [0|0] "" Vector__XXX
 SG_ DM12_10SPN_High : 325|3@1+ (65536,0) [0|0] "" Vector__XXX
 SG_ DM12_09SPN_High : 293|3@1+ (65536,0) [0|0] "" Vector__XXX
 SG_ DM12_08SPN_High : 261|3@1+ (65536,0) [0|0] "" Vector__XXX
 SG_ DM12_07SPN_High : 229|3@1+ (65536,0) [0|0] "" Vector__XXX
 SG_ DM12_06SPN_High : 197|3@1+ (65536,0) [0|0] "" Vector__XXX
 SG_ DM12_05SPN_High : 165|3@1+ (65536,0) [0|0] "" Vector__XXX
 SG_ DM12_04SPN_High : 133|3@1+ (65536,0) [0|0] "" Vector__XXX
 SG_ DM12_03SPN_High : 101|3@1+ (65536,0) [0|0] "" Vector__XXX
 SG_ DM12_02SPN_High : 69|3@1+ (65536,0) [0|0] "" Vector__XXX
 SG_ DM12_01SPN_High : 37|3@1+ (65536,0) [0|0] "" Vector__XXX
 SG_ DM12_01CM : 47|1@1+ (1,0) [0|0] "" Vector__XXX
 SG_ DM12_02CM : 79|1@1+ (1,0) [0|0] "" Vector__XXX
 SG_ DM12_03CM : 111|1@1+ (1,0) [0|0] "" Vector__XXX
 SG_ DM12_04CM : 143|1@1+ (1,0) [0|0] "" Vector__XXX
 SG_ DM12_05CM : 175|1@1+ (1,0) [0|0] "" Vector__XXX
 SG_ DM12_06CM : 207|1@1+ (1,0) [0|0] "" Vector__XXX
 SG_ DM12_07CM : 239|1@1+ (1,0) [0|0] "" Vector__XXX
 SG_ DM12_08CM : 271|1@1+ (1,0) [0|0] "" Vector__XXX
 SG_ DM12_09CM : 303|1@1+ (1,0) [0|0] "" Vector__XXX
 SG_ DM12_10CM : 335|1@1+ (1,0) [0|0] "" Vector__XXX
 SG_ DM12_11CM : 367|1@1+ (1,0) [0|0] "" Vector__XXX
 SG_ DM12_12CM : 399|1@1+ (1,0) [0|0] "" Vector__XXX
 SG_ DM12_13CM : 431|1@1+ (1,0) [0|0] "" Vector__XXX
 SG_ DM12_14CM : 463|1@1+ (1,0) [0|0] "" Vector__XXX
 SG_ DM12_15CM : 495|1@1+ (1,0) [0|0] "" Vector__XXX
 SG_ DM12_16CM : 527|1@1+ (1,0) [0|0] "" Vector__XXX
 SG_ DM12_17CM : 559|1@1+ (1,0) [0|0] "" Vector__XXX
 SG_ DM12_18CM : 591|1@1+ (1,0) [0|0] "" Vector__XXX
 SG_ DM12_19CM : 623|1@1+ (1,0) [0|0] "" Vector__XXX

BO_ 2566837246 DM11: 0 Vector__XXX

BO_ 2566836990 DM10: 8 Vector__XXX
 SG_ TestIdentifierSupported : 0|64@1+ (1,0) [1|1.8446744074e+19] "" Vector__XXX

BO_ 2566834942 DM01: 78 Vector__XXX
 SG_ FlashRedStopLamp : 12|2@1+ (1,0) [0|3] "" Vector__XXX
 SG_ FlashProtectLamp : 8|2@1+ (1,0) [0|3] "" Vector__XXX
 SG_ FlashMalfuncIndicatorLamp : 14|2@1+ (1,0) [0|3] "" Vector__XXX
 SG_ FlashAmberWarningLamp : 10|2@1+ (1,0) [0|3] "" Vector__XXX
 SG_ MalfunctionIndicatorLampStatus : 6|2@1+ (1,0) [0|3] "" Vector__XXX
 SG_ AmberWarningLampStatus : 2|2@1+ (1,0) [0|3] "" Vector__XXX
 SG_ RedStopLampStatus : 4|2@1+ (1,0) [0|3] "" Vector__XXX
 SG_ ProtectLampStatus : 0|2@1+ (1,0) [0|3] "" Vector__XXX
 SG_ DM01_01OC : 40|7@1+ (1,0) [0|0] "" Vector__XXX
 SG_ DM01_01FMI : 32|5@1+ (1,0) [0|0] "" Vector__XXX
 SG_ DM01_01SPN : 16|16@1+ (1,0) [0|0] "" Vector__XXX
 SG_ DM01_02OC : 72|7@1+ (1,0) [0|0] "" Vector__XXX
 SG_ DM01_02FMI : 64|5@1+ (1,0) [0|0] "" Vector__XXX
 SG_ DM01_02SPN : 48|16@1+ (1,0) [0|0] "" Vector__XXX
 SG_ DM01_03OC : 104|7@1+ (1,0) [0|0] "" Vector__XXX
 SG_ DM01_03FMI : 96|5@1+ (1,0) [0|0] "" Vector__XXX
 SG_ DM01_03SPN : 80|16@1+ (1,0) [0|0] "" Vector__XXX
 SG_ DM01_04OC : 136|7@1+ (1,0) [0|0] "" Vector__XXX
 SG_ DM01_04FMI : 128|5@1+ (1,0) [0|0] "" Vector__XXX
 SG_ DM01_04SPN : 112|16@1+ (1,0) [0|0] "" Vector__XXX
 SG_ DM01_05OC : 168|7@1+ (1,0) [0|0] "" Vector__XXX
 SG_ DM01_05FMI : 160|5@1+ (1,0) [0|0] "" Vector__XXX
 SG_ DM01_05SPN : 144|16@1+ (1,0) [0|0] "" Vector__XXX
 SG_ DM01_06OC : 200|7@1+ (1,0) [0|0] "" Vector__XXX
 SG_ DM01_06FMI : 192|5@1+ (1,0) [0|0] "" Vector__XXX
 SG_ DM01_06SPN : 176|16@1+ (1,0) [0|0] "" Vector__XXX
 SG_ DM01_07OC : 232|7@1+ (1,0) [0|0] "" Vector__XXX
 SG_ DM01_07FMI : 224|5@1+ (1,0) [0|0] "" Vector__XXX
 SG_ DM01_07SPN : 208|16@1+ (1,0) [0|0] "" Vector__XXX
 SG_ DM01_08OC : 264|7@1+ (1,0) [0|0] "" Vector__XXX
 SG_ DM01_08FMI : 256|5@1+ (1,0) [0|0] "" Vector__XXX
 SG_ DM01_08SPN : 240|16@1+ (1,0) [0|0] "" Vector__XXX
 SG_ DM01_09OC : 296|7@1+ (1,0) [0|0] "" Vector__XXX
 SG_ DM01_09FMI : 288|5@1+ (1,0) [0|0] "" Vector__XXX
 SG_ DM01_09SPN : 272|16@1+ (1,0) [0|0] "" Vector__XXX
 SG_ DM01_10OC : 328|7@1+ (1,0) [0|0] "" Vector__XXX
 SG_ DM01_10FMI : 320|5@1+ (1,0) [0|0] "" Vector__XXX
 SG_ DM01_10SPN : 304|16@1+ (1,0) [0|0] "" Vector__XXX
 SG_ DM01_11OC : 360|7@1+ (1,0) [0|0] "" Vector__XXX
 SG_ DM01_11FMI : 352|5@1+ (1,0) [0|0] "" Vector__XXX
 SG_ DM01_11SPN : 336|16@1+ (1,0) [0|0] "" Vector__XXX
 SG_ DM01_12OC : 392|7@1+ (1,0) [0|0] "" Vector__XXX
 SG_ DM01_12FMI : 384|5@1+ (1,0) [0|0] "" Vector__XXX
 SG_ DM01_12SPN : 368|16@1+ (1,0) [0|0] "" Vector__XXX
 SG_ DM01_13OC : 424|7@1+ (1,0) [0|0] "" Vector__XXX
 SG_ DM01_13FMI : 416|5@1+ (1,0) [0|0] "" Vector__XXX
 SG_ DM01_13SPN : 400|16@1+ (1,0) [0|0] "" Vector__XXX
 SG_ DM01_14OC : 456|7@1+ (1,0) [0|0] "" Vector__XXX
 SG_ DM01_14FMI : 448|5@1+ (1,0) [0|0] "" Vector__XXX
 SG_ DM01_14SPN : 432|16@1+ (1,0) [0|0] "" Vector__XXX
 SG_ DM01_15OC : 488|7@1+ (1,0) [0|0] "" Vector__XXX
 SG_ DM01_15FMI : 480|5@1+ (1,0) [0|0] "" Vector__XXX
 SG_ DM01_15SPN : 464|16@1+ (1,0) [0|0] "" Vector__XXX
 SG_ DM01_16OC : 520|7@1+ (1,0) [0|0] "" Vector__XXX
 SG_ DM01_16FMI : 512|5@1+ (1,0) [0|0] "" Vector__XXX
 SG_ DM01_16SPN : 496|16@1+ (1,0) [0|0] "" Vector__XXX
 SG_ DM01_17OC : 552|7@1+ (1,0) [0|0] "" Vector__XXX
 SG_ DM01_17FMI : 544|5@1+ (1,0) [0|0] "" Vector__XXX
 SG_ DM01_17SPN : 528|16@1+ (1,0) [0|0] "" Vector__XXX
 SG_ DM01_18OC : 584|7@1+ (1,0) [0|0] "" Vector__XXX
 SG_ DM01_18FMI : 576|5@1+ (1,0) [0|0] "" Vector__XXX
 SG_ DM01_18SPN : 560|16@1+ (1,0) [0|0] "" Vector__XXX
 SG_ DM01_19OC : 616|7@1+ (1,0) [0|0] "" Vector__XXX
 SG_ DM01_19FMI : 608|5@1+ (1,0) [0|0] "" Vector__XXX
 SG_ DM01_19SPN : 592|16@1+ (1,0) [0|0] "" Vector__XXX
 SG_ DM01_19SPN_High : 613|3@1+ (65536,0) [0|0] "" Vector__XXX
 SG_ DM01_18SPN_High : 581|3@1+ (65536,0) [0|0] "" Vector__XXX
 SG_ DM01_17SPN_High : 549|3@1+ (65536,0) [0|0] "" Vector__XXX
 SG_ DM01_16SPN_High : 517|3@1+ (65536,0) [0|0] "" Vector__XXX
 SG_ DM01_15SPN_High : 485|3@1+ (65536,0) [0|0] "" Vector__XXX
 SG_ DM01_14SPN_High : 453|3@1+ (65536,0) [0|0] "" Vector__XXX
 SG_ DM01_13SPN_High : 421|3@1+ (65536,0) [0|0] "" Vector__XXX
 SG_ DM01_12SPN_High : 389|3@1+ (65536,0) [0|0] "" Vector__XXX
 SG_ DM01_11SPN_High : 357|3@1+ (65536,0) [0|0] "" Vector__XXX
 SG_ DM01_10SPN_High : 325|3@1+ (65536,0) [0|0] "" Vector__XXX
 SG_ DM01_09SPN_High : 293|3@1+ (65536,0) [0|0] "" Vector__XXX
 SG_ DM01_08SPN_High : 261|3@1+ (65536,0) [0|0] "" Vector__XXX
 SG_ DM01_07SPN_High : 229|3@1+ (65536,0) [0|0] "" Vector__XXX
 SG_ DM01_06SPN_High : 197|3@1+ (65536,0) [0|0] "" Vector__XXX
 SG_ DM01_05SPN_High : 165|3@1+ (65536,0) [0|0] "" Vector__XXX
 SG_ DM01_04SPN_High : 133|3@1+ (65536,0) [0|0] "" Vector__XXX
 SG_ DM01_03SPN_High : 101|3@1+ (65536,0) [0|0] "" Vector__XXX
 SG_ DM01_02SPN_High : 69|3@1+ (65536,0) [0|0] "" Vector__XXX
 SG_ DM01_01SPN_High : 37|3@1+ (65536,0) [0|0] "" Vector__XXX
 SG_ DM01_01CM : 47|1@1+ (1,0) [0|0] "" Vector__XXX
 SG_ DM01_02CM : 79|1@1+ (1,0) [0|0] "" Vector__XXX
 SG_ DM01_03CM : 111|1@1+ (1,0) [0|0] "" Vector__XXX
 SG_ DM01_04CM : 143|1@1+ (1,0) [0|0] "" Vector__XXX
 SG_ DM01_05CM : 175|1@1+ (1,0) [0|0] "" Vector__XXX
 SG_ DM01_06CM : 207|1@1+ (1,0) [0|0] "" Vector__XXX
 SG_ DM01_07CM : 239|1@1+ (1,0) [0|0] "" Vector__XXX
 SG_ DM01_08CM : 271|1@1+ (1,0) [0|0] "" Vector__XXX
 SG_ DM01_09CM : 303|1@1+ (1,0) [0|0] "" Vector__XXX
 SG_ DM01_10CM : 335|1@1+ (1,0) [0|0] "" Vector__XXX
 SG_ DM01_11CM : 367|1@1+ (1,0) [0|0] "" Vector__XXX
 SG_ DM01_12CM : 399|1@1+ (1,0) [0|0] "" Vector__XXX
 SG_ DM01_13CM : 431|1@1+ (1,0) [0|0] "" Vector__XXX
 SG_ DM01_14CM : 463|1@1+ (1,0) [0|0] "" Vector__XXX
 SG_ DM01_15CM : 495|1@1+ (1,0) [0|0] "" Vector__XXX
 SG_ DM01_16CM : 527|1@1+ (1,0) [0|0] "" Vector__XXX
 SG_ DM01_17CM : 559|1@1+ (1,0) [0|0] "" Vector__XXX
 SG_ DM01_18CM : 591|1@1+ (1,0) [0|0] "" Vector__XXX
 SG_ DM01_19CM : 623|1@1+ (1,0) [0|0] "" Vector__XXX

BO_ 2566739198 DM52: 78 Vector__XXX
 SG_ FlashRedStopLamp : 12|2@1+ (1,0) [0|3] "" Vector__XXX
 SG_ FlashProtectLamp : 8|2@1+ (1,0) [0|3] "" Vector__XXX
 SG_ FlashMalfuncIndicatorLamp : 14|2@1+ (1,0) [0|3] "" Vector__XXX
 SG_ FlashAmberWarningLamp : 10|2@1+ (1,0) [0|3] "" Vector__XXX
 SG_ MalfunctionIndicatorLampStatus : 6|2@1+ (1,0) [0|3] "" Vector__XXX
 SG_ AmberWarningLampStatus : 2|2@1+ (1,0) [0|3] "" Vector__XXX
 SG_ RedStopLampStatus : 4|2@1+ (1,0) [0|3] "" Vector__XXX
 SG_ ProtectLampStatus : 0|2@1+ (1,0) [0|3] "" Vector__XXX
 SG_ DM52_01OC : 40|7@1+ (1,0) [0|0] "" Vector__XXX
 SG_ DM52_01FMI : 32|5@1+ (1,0) [0|0] "" Vector__XXX
 SG_ DM52_01SPN : 16|16@1+ (1,0) [0|0] "" Vector__XXX
 SG_ DM52_02OC : 72|7@1+ (1,0) [0|0] "" Vector__XXX
 SG_ DM52_02FMI : 64|5@1+ (1,0) [0|0] "" Vector__XXX
 SG_ DM52_02SPN : 48|16@1+ (1,0) [0|0] "" Vector__XXX
 SG_ DM52_03OC : 104|7@1+ (1,0) [0|0] "" Vector__XXX
 SG_ DM52_03FMI : 96|5@1+ (1,0) [0|0] "" Vector__XXX
 SG_ DM52_03SPN : 80|16@1+ (1,0) [0|0] "" Vector__XXX
 SG_ DM52_04OC : 136|7@1+ (1,0) [0|0] "" Vector__XXX
 SG_ DM52_04FMI : 128|5@1+ (1,0) [0|0] "" Vector__XXX
 SG_ DM52_04SPN : 112|16@1+ (1,0) [0|0] "" Vector__XXX
 SG_ DM52_05OC : 168|7@1+ (1,0) [0|0] "" Vector__XXX
 SG_ DM52_05FMI : 160|5@1+ (1,0) [0|0] "" Vector__XXX
 SG_ DM52_05SPN : 144|16@1+ (1,0) [0|0] "" Vector__XXX
 SG_ DM52_06OC : 200|7@1+ (1,0) [0|0] "" Vector__XXX
 SG_ DM52_06FMI : 192|5@1+ (1,0) [0|0] "" Vector__XXX
 SG_ DM52_06SPN : 176|16@1+ (1,0) [0|0] "" Vector__XXX
 SG_ DM52_07OC : 232|7@1+ (1,0) [0|0] "" Vector__XXX
 SG_ DM52_07FMI : 224|5@1+ (1,0) [0|0] "" Vector__XXX
 SG_ DM52_07SPN : 208|16@1+ (1,0) [0|0] "" Vector__XXX
 SG_ DM52_08OC : 264|7@1+ (1,0) [0|0] "" Vector__XXX
 SG_ DM52_08FMI : 256|5@1+ (1,0) [0|0] "" Vector__XXX
 SG_ DM52_08SPN : 240|16@1+ (1,0) [0|0] "" Vector__XXX
 SG_ DM52_09OC : 296|7@1+ (1,0) [0|0] "" Vector__XXX
 SG_ DM52_09FMI : 288|5@1+ (1,0) [0|0] "" Vector__XXX
 SG_ DM52_09SPN : 272|16@1+ (1,0) [0|0] "" Vector__XXX
 SG_ DM52_10OC : 328|7@1+ (1,0) [0|0] "" Vector__XXX
 SG_ DM52_10FMI : 320|5@1+ (1,0) [0|0] "" Vector__XXX
 SG_ DM52_10SPN : 304|16@1+ (1,0) [0|0] "" Vector__XXX
 SG_ DM52_11OC : 360|7@1+ (1,0) [0|0] "" Vector__XXX
 SG_ DM52_11FMI : 352|5@1+ (1,0) [0|0] "" Vector__XXX
 SG_ DM52_11SPN : 336|16@1+ (1,0) [0|0] "" Vector__XXX
 SG_ DM52_12OC : 392|7@1+ (1,0) [0|0] "" Vector__XXX
 SG_ DM52_12FMI : 384|5@1+ (1,0) [0|0] "" Vector__XXX
 SG_ DM52_12SPN : 368|16@1+ (1,0) [0|0] "" Vector__XXX
 SG_ DM52_13OC : 424|7@1+ (1,0) [0|0] "" Vector__XXX
 SG_ DM52_13FMI : 416|5@1+ (1,0) [0|0] "" Vector__XXX
 SG_ DM52_13SPN : 400|16@1+ (1,0) [0|0] "" Vector__XXX
 SG_ DM52_14OC : 456|7@1+ (1,0) [0|0] "" Vector__XXX
 SG_ DM52_14FMI : 448|5@1+ (1,0) [0|0] "" Vector__XXX
 SG_ DM52_14SPN : 432|16@1+ (1,0) [0|0] "" Vector__XXX
 SG_ DM52_15OC : 488|7@1+ (1,0) [0|0] "" Vector__XXX
 SG_ DM52_15FMI : 480|5@1+ (1,0) [0|0] "" Vector__XXX
 SG_ DM52_15SPN : 464|16@1+ (1,0) [0|0] "" Vector__XXX
 SG_ DM52_16OC : 520|7@1+ (1,0) [0|0] "" Vector__XXX
 SG_ DM52_16FMI : 512|5@1+ (1,0) [0|0] "" Vector__XXX
 SG_ DM52_16SPN : 496|16@1+ (1,0) [0|0] "" Vector__XXX
 SG_ DM52_17OC : 552|7@1+ (1,0) [0|0] "" Vector__XXX
 SG_ DM52_17FMI : 544|5@1+ (1,0) [0|0] "" Vector__XXX
 SG_ DM52_17SPN : 528|16@1+ (1,0) [0|0] "" Vector__XXX
 SG_ DM52_18OC : 584|7@1+ (1,0) [0|0] "" Vector__XXX
 SG_ DM52_18FMI : 576|5@1+ (1,0) [0|0] "" Vector__XXX
 SG_ DM52_18SPN : 560|16@1+ (1,0) [0|0] "" Vector__XXX
 SG_ DM52_19OC : 616|7@1+ (1,0) [0|0] "" Vector__XXX
 SG_ DM52_19FMI : 608|5@1+ (1,0) [0|0] "" Vector__XXX
 SG_ DM52_19SPN : 592|16@1+ (1,0) [0|0] "" Vector__XXX
 SG_ DM52_19SPN_High : 613|3@1+ (65536,0) [0|0] "" Vector__XXX
 SG_ DM52_18SPN_High : 581|3@1+ (65536,0) [0|0] "" Vector__XXX
 SG_ DM52_17SPN_High : 549|3@1+ (65536,0) [0|0] "" Vector__XXX
 SG_ DM52_16SPN_High : 517|3@1+ (65536,0) [0|0] "" Vector__XXX
 SG_ DM52_15SPN_High : 485|3@1+ (65536,0) [0|0] "" Vector__XXX
 SG_ DM52_14SPN_High : 453|3@1+ (65536,0) [0|0] "" Vector__XXX
 SG_ DM52_13SPN_High : 421|3@1+ (65536,0) [0|0] "" Vector__XXX
 SG_ DM52_12SPN_High : 389|3@1+ (65536,0) [0|0] "" Vector__XXX
 SG_ DM52_11SPN_High : 357|3@1+ (65536,0) [0|0] "" Vector__XXX
 SG_ DM52_10SPN_High : 325|3@1+ (65536,0) [0|0] "" Vector__XXX
 SG_ DM52_09SPN_High : 293|3@1+ (65536,0) [0|0] "" Vector__XXX
 SG_ DM52_08SPN_High : 261|3@1+ (65536,0) [0|0] "" Vector__XXX
 SG_ DM52_07SPN_High : 229|3@1+ (65536,0) [0|0] "" Vector__XXX
 SG_ DM52_06SPN_High : 197|3@1+ (65536,0) [0|0] "" Vector__XXX
 SG_ DM52_05SPN_High : 165|3@1+ (65536,0) [0|0] "" Vector__XXX
 SG_ DM52_04SPN_High : 133|3@1+ (65536,0) [0|0] "" Vector__XXX
 SG_ DM52_03SPN_High : 101|3@1+ (65536,0) [0|0] "" Vector__XXX
 SG_ DM52_02SPN_High : 69|3@1+ (65536,0) [0|0] "" Vector__XXX
 SG_ DM52_01SPN_High : 37|3@1+ (65536,0) [0|0] "" Vector__XXX
 SG_ DM52_01CM : 47|1@1+ (1,0) [0|0] "" Vector__XXX
 SG_ DM52_02CM : 79|1@1+ (1,0) [0|0] "" Vector__XXX
 SG_ DM52_03CM : 111|1@1+ (1,0) [0|0] "" Vector__XXX
 SG_ DM52_04CM : 143|1@1+ (1,0) [0|0] "" Vector__XXX
 SG_ DM52_05CM : 175|1@1+ (1,0) [0|0] "" Vector__XXX
 SG_ DM52_06CM : 207|1@1+ (1,0) [0|0] "" Vector__XXX
 SG_ DM52_07CM : 239|1@1+ (1,0) [0|0] "" Vector__XXX
 SG_ DM52_08CM : 271|1@1+ (1,0) [0|0] "" Vector__XXX
 SG_ DM52_09CM : 303|1@1+ (1,0) [0|0] "" Vector__XXX
 SG_ DM52_10CM : 335|1@1+ (1,0) [0|0] "" Vector__XXX
 SG_ DM52_11CM : 367|1@1+ (1,0) [0|0] "" Vector__XXX
 SG_ DM52_12CM : 399|1@1+ (1,0) [0|0] "" Vector__XXX
 SG_ DM52_13CM : 431|1@1+ (1,0) [0|0] "" Vector__XXX
 SG_ DM52_14CM : 463|1@1+ (1,0) [0|0] "" Vector__XXX
 SG_ DM52_15CM : 495|1@1+ (1,0) [0|0] "" Vector__XXX
 SG_ DM52_16CM : 527|1@1+ (1,0) [0|0] "" Vector__XXX
 SG_ DM52_17CM : 559|1@1+ (1,0) [0|0] "" Vector__XXX
 SG_ DM52_18CM : 591|1@1+ (1,0) [0|0] "" Vector__XXX
 SG_ DM52_19CM : 623|1@1+ (1,0) [0|0] "" Vector__XXX

BO_ 2566739454 DM51: 78 Vector__XXX
 SG_ FlashRedStopLamp : 12|2@1+ (1,0) [0|3] "" Vector__XXX
 SG_ FlashProtectLamp : 8|2@1+ (1,0) [0|3] "" Vector__XXX
 SG_ FlashMalfuncIndicatorLamp : 14|2@1+ (1,0) [0|3] "" Vector__XXX
 SG_ FlashAmberWarningLamp : 10|2@1+ (1,0) [0|3] "" Vector__XXX
 SG_ MalfunctionIndicatorLampStatus : 6|2@1+ (1,0) [0|3] "" Vector__XXX
 SG_ AmberWarningLampStatus : 2|2@1+ (1,0) [0|3] "" Vector__XXX
 SG_ RedStopLampStatus : 4|2@1+ (1,0) [0|3] "" Vector__XXX
 SG_ ProtectLampStatus : 0|2@1+ (1,0) [0|3] "" Vector__XXX
 SG_ DM51_01OC : 40|7@1+ (1,0) [0|0] "" Vector__XXX
 SG_ DM51_01FMI : 32|5@1+ (1,0) [0|0] "" Vector__XXX
 SG_ DM51_01SPN : 16|16@1+ (1,0) [0|0] "" Vector__XXX
 SG_ DM51_02OC : 72|7@1+ (1,0) [0|0] "" Vector__XXX
 SG_ DM51_02FMI : 64|5@1+ (1,0) [0|0] "" Vector__XXX
 SG_ DM51_02SPN : 48|16@1+ (1,0) [0|0] "" Vector__XXX
 SG_ DM51_03OC : 104|7@1+ (1,0) [0|0] "" Vector__XXX
 SG_ DM51_03FMI : 96|5@1+ (1,0) [0|0] "" Vector__XXX
 SG_ DM51_03SPN : 80|16@1+ (1,0) [0|0] "" Vector__XXX
 SG_ DM51_04OC : 136|7@1+ (1,0) [0|0] "" Vector__XXX
 SG_ DM51_04FMI : 128|5@1+ (1,0) [0|0] "" Vector__XXX
 SG_ DM51_04SPN : 112|16@1+ (1,0) [0|0] "" Vector__XXX
 SG_ DM51_05OC : 168|7@1+ (1,0) [0|0] "" Vector__XXX
 SG_ DM51_05FMI : 160|5@1+ (1,0) [0|0] "" Vector__XXX
 SG_ DM51_05SPN : 144|16@1+ (1,0) [0|0] "" Vector__XXX
 SG_ DM51_06OC : 200|7@1+ (1,0) [0|0] "" Vector__XXX
 SG_ DM51_06FMI : 192|5@1+ (1,0) [0|0] "" Vector__XXX
 SG_ DM51_06SPN : 176|16@1+ (1,0) [0|0] "" Vector__XXX
 SG_ DM51_07OC : 232|7@1+ (1,0) [0|0] "" Vector__XXX
 SG_ DM51_07FMI : 224|5@1+ (1,0) [0|0] "" Vector__XXX
 SG_ DM51_07SPN : 208|16@1+ (1,0) [0|0] "" Vector__XXX
 SG_ DM51_08OC : 264|7@1+ (1,0) [0|0] "" Vector__XXX
 SG_ DM51_08FMI : 256|5@1+ (1,0) [0|0] "" Vector__XXX
 SG_ DM51_08SPN : 240|16@1+ (1,0) [0|0] "" Vector__XXX
 SG_ DM51_09OC : 296|7@1+ (1,0) [0|0] "" Vector__XXX
 SG_ DM51_09FMI : 288|5@1+ (1,0) [0|0] "" Vector__XXX
 SG_ DM51_09SPN : 272|16@1+ (1,0) [0|0] "" Vector__XXX
 SG_ DM51_10OC : 328|7@1+ (1,0) [0|0] "" Vector__XXX
 SG_ DM51_10FMI : 320|5@1+ (1,0) [0|0] "" Vector__XXX
 SG_ DM51_10SPN : 304|16@1+ (1,0) [0|0] "" Vector__XXX
 SG_ DM51_11OC : 360|7@1+ (1,0) [0|0] "" Vector__XXX
 SG_ DM51_11FMI : 352|5@1+ (1,0) [0|0] "" Vector__XXX
 SG_ DM51_11SPN : 336|16@1+ (1,0) [0|0] "" Vector__XXX
 SG_ DM51_12OC : 392|7@1+ (1,0) [0|0] "" Vector__XXX
 SG_ DM51_12FMI : 384|5@1+ (1,0) [0|0] "" Vector__XXX
 SG_ DM51_12SPN : 368|16@1+ (1,0) [0|0] "" Vector__XXX
 SG_ DM51_13OC : 424|7@1+ (1,0) [0|0] "" Vector__XXX
 SG_ DM51_13FMI : 416|5@1+ (1,0) [0|0] "" Vector__XXX
 SG_ DM51_13SPN : 400|16@1+ (1,0) [0|0] "" Vector__XXX
 SG_ DM51_14OC : 456|7@1+ (1,0) [0|0] "" Vector__XXX
 SG_ DM51_14FMI : 448|5@1+ (1,0) [0|0] "" Vector__XXX
 SG_ DM51_14SPN : 432|16@1+ (1,0) [0|0] "" Vector__XXX
 SG_ DM51_15OC : 488|7@1+ (1,0) [0|0] "" Vector__XXX
 SG_ DM51_15FMI : 480|5@1+ (1,0) [0|0] "" Vector__XXX
 SG_ DM51_15SPN : 464|16@1+ (1,0) [0|0] "" Vector__XXX
 SG_ DM51_16OC : 520|7@1+ (1,0) [0|0] "" Vector__XXX
 SG_ DM51_16FMI : 512|5@1+ (1,0) [0|0] "" Vector__XXX
 SG_ DM51_16SPN : 496|16@1+ (1,0) [0|0] "" Vector__XXX
 SG_ DM51_17OC : 552|7@1+ (1,0) [0|0] "" Vector__XXX
 SG_ DM51_17FMI : 544|5@1+ (1,0) [0|0] "" Vector__XXX
 SG_ DM51_17SPN : 528|16@1+ (1,0) [0|0] "" Vector__XXX
 SG_ DM51_18OC : 584|7@1+ (1,0) [0|0] "" Vector__XXX
 SG_ DM51_18FMI : 576|5@1+ (1,0) [0|0] "" Vector__XXX
 SG_ DM51_18SPN : 560|16@1+ (1,0) [0|0] "" Vector__XXX
 SG_ DM51_19OC : 616|7@1+ (1,0) [0|0] "" Vector__XXX
 SG_ DM51_19FMI : 608|5@1+ (1,0) [0|0] "" Vector__XXX
 SG_ DM51_19SPN : 592|16@1+ (1,0) [0|0] "" Vector__XXX
 SG_ DM51_19SPN_High : 613|3@1+ (65536,0) [0|0] "" Vector__XXX
 SG_ DM51_18SPN_High : 581|3@1+ (65536,0) [0|0] "" Vector__XXX
 SG_ DM51_17SPN_High : 549|3@1+ (65536,0) [0|0] "" Vector__XXX
 SG_ DM51_16SPN_High : 517|3@1+ (65536,0) [0|0] "" Vector__XXX
 SG_ DM51_15SPN_High : 485|3@1+ (65536,0) [0|0] "" Vector__XXX
 SG_ DM51_14SPN_High : 453|3@1+ (65536,0) [0|0] "" Vector__XXX
 SG_ DM51_13SPN_High : 421|3@1+ (65536,0) [0|0] "" Vector__XXX
 SG_ DM51_12SPN_High : 389|3@1+ (65536,0) [0|0] "" Vector__XXX
 SG_ DM51_11SPN_High : 357|3@1+ (65536,0) [0|0] "" Vector__XXX
 SG_ DM51_10SPN_High : 325|3@1+ (65536,0) [0|0] "" Vector__XXX
 SG_ DM51_09SPN_High : 293|3@1+ (65536,0) [0|0] "" Vector__XXX
 SG_ DM51_08SPN_High : 261|3@1+ (65536,0) [0|0] "" Vector__XXX
 SG_ DM51_07SPN_High : 229|3@1+ (65536,0) [0|0] "" Vector__XXX
 SG_ DM51_06SPN_High : 197|3@1+ (65536,0) [0|0] "" Vector__XXX
 SG_ DM51_05SPN_High : 165|3@1+ (65536,0) [0|0] "" Vector__XXX
 SG_ DM51_04SPN_High : 133|3@1+ (65536,0) [0|0] "" Vector__XXX
 SG_ DM51_03SPN_High : 101|3@1+ (65536,0) [0|0] "" Vector__XXX
 SG_ DM51_02SPN_High : 69|3@1+ (65536,0) [0|0] "" Vector__XXX
 SG_ DM51_01SPN_High : 37|3@1+ (65536,0) [0|0] "" Vector__XXX
 SG_ DM51_01CM : 47|1@1+ (1,0) [0|0] "" Vector__XXX
 SG_ DM51_02CM : 79|1@1+ (1,0) [0|0] "" Vector__XXX
 SG_ DM51_03CM : 111|1@1+ (1,0) [0|0] "" Vector__XXX
 SG_ DM51_04CM : 143|1@1+ (1,0) [0|0] "" Vector__XXX
 SG_ DM51_05CM : 175|1@1+ (1,0) [0|0] "" Vector__XXX
 SG_ DM51_06CM : 207|1@1+ (1,0) [0|0] "" Vector__XXX
 SG_ DM51_07CM : 239|1@1+ (1,0) [0|0] "" Vector__XXX
 SG_ DM51_08CM : 271|1@1+ (1,0) [0|0] "" Vector__XXX
 SG_ DM51_09CM : 303|1@1+ (1,0) [0|0] "" Vector__XXX
 SG_ DM51_10CM : 335|1@1+ (1,0) [0|0] "" Vector__XXX
 SG_ DM51_11CM : 367|1@1+ (1,0) [0|0] "" Vector__XXX
 SG_ DM51_12CM : 399|1@1+ (1,0) [0|0] "" Vector__XXX
 SG_ DM51_13CM : 431|1@1+ (1,0) [0|0] "" Vector__XXX
 SG_ DM51_14CM : 463|1@1+ (1,0) [0|0] "" Vector__XXX
 SG_ DM51_15CM : 495|1@1+ (1,0) [0|0] "" Vector__XXX
 SG_ DM51_16CM : 527|1@1+ (1,0) [0|0] "" Vector__XXX
 SG_ DM51_17CM : 559|1@1+ (1,0) [0|0] "" Vector__XXX
 SG_ DM51_18CM : 591|1@1+ (1,0) [0|0] "" Vector__XXX
 SG_ DM51_19CM : 623|1@1+ (1,0) [0|0] "" Vector__XXX

CM_ BO_ 2564095742 "Data security";
CM_ BO_ 2566742270 "Harmonized B1 Failure Counts";
CM_ SG_ 2566742270 FailureSpecificB1Counter "The Failure Specific B1 Counter provides an individual B1 counter";
CM_ SG_ 2566742270 DM40_01FMI "The FMI defines the type of failure detected in the subsystem identified by an SPN.";
CM_ SG_ 2566742270 DM40_01SPN_High "SPN #1 (Conversion Version 4)";
CM_ SG_ 2566742270 DM40_01SPN "SPN #1 (Conversion Version 4)";
CM_ BO_ 2566742526 "Harmonized Cumulative Continuous Malfunction Indicator - System";
CM_ SG_ 2566742526 SysGreatestB1Counter "System Greatest B1 Counter";
CM_ SG_ 2566742526 SysCumulativeContinuousMITime "System Cumulative Continuous MI Time";
CM_ BO_ 2566742782 "Harmonized Global Regulation Description";
CM_ SG_ 2566742782 RegulationDescription "Global Technical Regulation Description";
CM_ BO_ 2566743038 "Harmonized Roadworthiness - System";
CM_ SG_ 2566743038 SysIncompleteMonitorCount "System Incomplete Monitor Count";
CM_ SG_ 2566743038 SysMalIndActivationMode "System Malfunction Indicator Status";
CM_ SG_ 2566743038 SysMalIndDisplayStrategy "System Malfunction Indicator Display";
CM_ SG_ 2566743038 SysContinuousMalfunctionInd "System Continuous Malfunction Indicator";
CM_ SG_ 2566743038 SysNonRoadworthyCompCount "System Non-Roadworthy Component Count";
CM_ BO_ 2566743294 "Harmonized Roadworthiness - Vehicle";
CM_ SG_ 2566743294 VehicleCurrentMIAccumTime "Vehicle Current MI Accumulated Time";
CM_ SG_ 2566743294 VehicleIncompleteMonitorCount "Vehicle Incomplete Monitor Count";
CM_ SG_ 2566743294 VehicleMalfunctionIndActMode "Vehicle Malfunction Indicator Status ";
CM_ SG_ 2566743294 VehicleMalfunctionIndStrategy "Vehicle Malfunction Indicator Display Strategy ";
CM_ SG_ 2566743294 VehicleContinuousMalfunctionInd "Vehicle Continuous Malfunction Indicator";
CM_ SG_ 2566743294 VehicleNonRoadworthyCompCount "Vehicle Non-Roadworthy Component Count";
CM_ BO_ 2560687870 "NTE Status. The status of engine operating in the NTE control areas for given pollutants, such as NOx and PM";
CM_ SG_ 2560687870 PMNTEDeficiencyAreaStatus "Status of engine operation within the PM NTE Deficiency Area";
CM_ SG_ 2560687870 MnfcPMNTECarveOutAreaStatus "Status of engine operation within the manufacturer specific PM NTE carve out area";
CM_ SG_ 2560687870 PMNTEControlAreaStatus "Status of engine operation within the bounded region of the engine's torque and speed map.";
CM_ SG_ 2560687870 NOxNTEDeficiencyAreaStatus "Status of engine operation within the NOx NTE Deficiency Area";
CM_ SG_ 2560687870 MnfcNOxNTECarveOutAreaStatus "Status of engine operation within the bounded region of the engine's torque and speed map.";
CM_ SG_ 2560687870 NOxNTEControlAreaStatus "Status of engine operation within the bounded region of the engine's torque and speed map.";
CM_ BO_ 2292317950 "Emission Increasing Auxiliary Emission Control Device Active Time";
CM_ SG_ 2292317950 AECDEngineHours1Timer2 "The total engine running hours recorded in the second timer for the EI-AECD";
CM_ SG_ 2292317950 AECDEngineHours1Timer1 "The total engine running hours recorded in the first timer for the EI-AECD";
CM_ SG_ 2292317950 AECDNumber1 "The manufacturer assigned number for the specific EI-AECD";
CM_ BO_ 2560884478 "DTC to Lamp Association. This message shall provide the applicable lamp for each individual DTC";
CM_ SG_ 2560884478 DTCWarnLampSupportStatus "Lamp support status";
CM_ SG_ 2560884478 DTCWarnLampSupportFlash "Lamp support status";
CM_ SG_ 2560884478 DTCStopLampSupportStatus "Lamp support status";
CM_ SG_ 2560884478 DTCStopLampSupportFlash "Lamp support status";
CM_ SG_ 2560884478 DTCProtectLampSupportStatus "Lamp support status";
CM_ SG_ 2560884478 DTCProtectLampSupportFlash "Lamp support status";
CM_ SG_ 2560884478 DTCMilSupportStatus "Lamp support status";
CM_ SG_ 2560884478 DTCMilSupportFlash "Lamp support status";
CM_ BO_ 2560950014 "Scaled Test Results. This message conveys the scaled test results for the applicable test requested in DM7.";
CM_ SG_ 2560950014 TestLimitMinimum "The test value must be greater than or equal to Test Limit Minimum in order for the test to pass";
CM_ SG_ 2560950014 TestLimitMaximum "The test value must be less than or equal to Test Limit Maximum in order for the test to pass.";
CM_ SG_ 2560950014 TestValue "The test value collected during the test.";
CM_ SG_ 2560950014 SlotId "The SLOT Identifer is used to determine the multiplier and offset to be used to scale the test value.";
CM_ SG_ 2560950014 TestIdentifier "Test Identifier";
CM_ SG_ 2560950014 DM30_01FMI "The FMI defines the type of failure detected in the subsystem identified by an SPN.";
CM_ SG_ 2560950014 DM30_01SPN_High "SPN #1 (Conversion Version 4)";
CM_ SG_ 2560950014 DM30_01SPN "SPN #1 (Conversion Version 4)";
CM_ BO_ 2566836478 "Test Results for Non-Continuously Monitored Systems";
CM_ SG_ 2566836478 TestLimitMinimum "The threshold which the test value must be above to pass the test.";
CM_ SG_ 2566836478 TestLimitMaximum "The threshold which the test value must be below to pass the test.";
CM_ SG_ 2566836478 TestValue "The test value collected during the test.";
CM_ SG_ 2566836478 TestType "Identifies the non-continously monitored component identifier that was tested.";
CM_ SG_ 2566836478 TestIdentifier "Designates the test to be run.";
CM_ BO_ 2565078782 "Command Non-Continuously Monitored Test";
CM_ SG_ 2565078782 TestIdentifier "Designates the test to be run.";
CM_ SG_ 2565078782 DM07_01FMI "The FMI defines the type of failure detected in the subsystem identified by an SPN.";
CM_ BO_ 2566836222 "Emission-Related Pending Diagnostic Trouble Codes. The purpose of this DM is to enable the external test equipment to obtain pending diagnostic trouble codes. The definition of a pending DTC varies according to the applicable regulatory guidance. Some regulations define pending to be a DTC detected during current or last completed driving cycle for emission-related components/systems";
CM_ SG_ 2566836222 FlashRedStopLamp "This parameter provides the capability to flash the RSL (SPN 3039).";
CM_ SG_ 2566836222 FlashProtectLamp "This parameter provides the capability to flash the engine protect lamp (SPN 3041).";
CM_ SG_ 2566836222 FlashMalfuncIndicatorLamp "This parameter provides the capability to flash the MIL (SPN 3038).";
CM_ SG_ 2566836222 FlashAmberWarningLamp "This parameter provides the capability to flash the AWL (SPN 3040). ";
CM_ SG_ 2566836222 MalfunctionIndicatorLampStatus "A lamp used to relay only emissions-related trouble code information.";
CM_ SG_ 2566836222 RedStopLampStatus "This lamp is uesed to relay trouble code information that is of a severe enought condition that it warrants stopping the vehicle.";
CM_ SG_ 2566836222 AmberWarningLampStatus "This lamp is used to relay trouble code information that is reporting a problem with the vehicle system but the vehicle need
not be immediately stopped.";
CM_ SG_ 2566836222 ProtectLampStatus "This lamp is used to relay trouble code informatio that is reporting a problem with a vehicle system that is most
probably not electronic subsystem related.";
CM_ BO_ 2566835966 "Diagnostic Readiness 1. This message reports the diagnostics information that relates to diagnostic readiness";
CM_ SG_ 2566835966 OBDCompliance "Identifies the OBD compliance capabilityof the responding controller.";
CM_ SG_ 2566835966 PreviouslyActiveTroubleCodeCount "Identifies the number of previously active trouble codes that are present in a specific controller.";
CM_ SG_ 2566835966 ActiveTroubleCodeCount "Identifies the number of active trouble codes that are present in a specific controller.";
CM_ BO_ 2566835710 "Freeze Frame Parameters. This message is defined as the list of recorded parameters at the time a diagnostic trouble code was captured. The freeze frame recorded for each diagnostic trouble code will contain the required parameters first, and then any manufacturer-specific information";
CM_ SG_ 2566835710 EngIntakeManifold1Press "The gage pressure measurement of the air intake manifold.";
CM_ SG_ 2566835710 FreezeFrameLength "The freeze frame length shall be equal to the number of bytes in the required parameters plus the number of bytes in the
manufacturer specific parameters.";
CM_ SG_ 2566835710 EngSpeed "Actual engine speed which is calculated over a minimum crankshaft angle of 720 degrees divided by the number of cylinders.";
CM_ SG_ 2566835710 EngTorqueMode "State signal which indicates which engine torque mode is currently generating, limiting, or controlling the torque.";
CM_ SG_ 2566835710 WheelBasedVehicleSpeed "Speed of the vehicle as calculated from wheel or tailshaft speed.";
CM_ SG_ 2566835710 EngPercentLoadAtCurrentSpeed "The ratio of actual engine percent torque (indicated) to maximum indicated torque available at the current engine speed,";
CM_ BO_ 2566835454 "Diagnostic Data Clear/Reset of Previously Active DTCs";
CM_ BO_ 2566764542 "Expanded Freeze Frame";
CM_ SG_ 2566764542 ExpandedFreezeFrameLength "The freeze frame length shall be equal to the number of bytes in the required parameters plus the number of bytes in the
manufacturer specific parameters.";
CM_ BO_ 2566764286 "SPN Support. This message is used to identify those SPNs supported by the product for freeze frames and data stream messages.";
CM_ SG_ 2566764286 SPNSupported1High "This parameter defines the SPN(s) that is/are supported for the freeze frame and/or data stream information.";
CM_ SG_ 2566764286 SPNSupportTypeSTR3 "This parameter defines whether the applicable parameter (that is the SPN) is supported in the freeze frame, the data stream or both the freeze frame and data stream.";
CM_ SG_ 2566764286 SPNSupportTypeSTR2 "This parameter defines whether the applicable parameter (that is the SPN) is supported in the freeze frame, the data stream or both the freeze frame and data stream.";
CM_ SG_ 2566764286 SPNSupportTypeEFF3 "This parameter defines whether the applicable parameter (that is the SPN) is supported in the freeze frame, the data stream or both the freeze frame and data stream.";
CM_ SG_ 2566764286 SPNSupportTypeEFF2 "This parameter defines whether the applicable parameter (that is the SPN) is supported in the freeze frame, the data stream or both the freeze frame and data stream.";
CM_ SG_ 2566764286 SPNSupportTypeDS3 "This parameter defines whether the applicable parameter (that is the SPN) is supported in the freeze frame, the data stream or both the freeze frame and data stream.";
CM_ SG_ 2566764286 SPNSupportTypeDS2 "This parameter defines whether the applicable parameter (that is the SPN) is supported in the freeze frame, the data stream or both the freeze frame and data stream.";
CM_ SG_ 2566764286 SPNSupported3High "This parameter defines the SPN(s) that is/are supported for the freeze frame and/or data stream information.";
CM_ SG_ 2566764286 SPNSupported2High "This parameter defines the SPN(s) that is/are supported for the freeze frame and/or data stream information.";
CM_ SG_ 2566764286 SPNSupported3 "This parameter defines the SPN(s) that is/are supported for the freeze frame and/or data stream information.";
CM_ SG_ 2566764286 SPNSupported2 "This parameter defines the SPN(s) that is/are supported for the freeze frame and/or data stream information.";
CM_ SG_ 2566764286 SPNDataLength3 "The number of data bytes associated with the SPN in the Freeze Frame.";
CM_ SG_ 2566764286 SPNSupportTypeSTR1 "This parameter defines whether the applicable parameter (that is the SPN) is supported in the freeze frame, the data stream or both the freeze frame and data stream.";
CM_ SG_ 2566764286 SPNSupportTypeDS1 "This parameter defines whether the applicable parameter (that is the SPN) is supported in the freeze frame, the data stream or both the freeze frame and data stream.";
CM_ SG_ 2566764286 SPNSupportTypeEFF1 "This parameter defines whether the applicable parameter (that is the SPN) is supported in the freeze frame, the data stream or both the freeze frame and data stream.";
CM_ SG_ 2566764286 SPNDataLength2 "The number of data bytes associated with the SPN in the Freeze Frame.";
CM_ SG_ 2566764286 SPNDataLength1 "The number of data bytes associated with the SPN in the Freeze Frame.";
CM_ SG_ 2566764286 SPNSupported1 "This parameter defines the SPN(s) that is/are supported for the freeze frame and/or data stream information.";
CM_ BO_ 2566764030 "Emission-Related Previously MIL-On Diagnostic Trouble Codes";
CM_ SG_ 2566764030 FlashRedStopLamp "This parameter provides the capability to flash the RSL (SPN 3039).";
CM_ SG_ 2566764030 FlashProtectLamp "This parameter provides the capability to flash the engine protect lamp (SPN 3041).";
CM_ SG_ 2566764030 FlashMalfuncIndicatorLamp "This parameter provides the capability to flash the MIL (SPN 3038).";
CM_ SG_ 2566764030 FlashAmberWarningLamp "This parameter provides the capability to flash the AWL (SPN 3040). ";
CM_ SG_ 2566764030 MalfunctionIndicatorLampStatus "A lamp used to relay only emissions-related trouble code information.";
CM_ SG_ 2566764030 RedStopLampStatus "This lamp is uesed to relay trouble code information that is of a severe enought condition that it warrants stopping the vehicle.";
CM_ SG_ 2566764030 AmberWarningLampStatus "This lamp is used to relay trouble code information that is reporting a problem with the vehicle system but the vehicle need
not be immediately stopped.";
CM_ SG_ 2566764030 ProtectLampStatus "This lamp is used to relay trouble code informatio that is reporting a problem with a vehicle system that is most
probably not electronic subsystem related.";
CM_ BO_ 2562981630 "Individual Clear/Reset of Active and Previously Active DTC";
CM_ SG_ 2562981630 DM22_01SPN "SPN #1 (Conversion Version 4)";
CM_ SG_ 2562981630 DM22_01SPN_High "SPN #1 (Conversion Version 4)";
CM_ SG_ 2562981630 DM22_01FMI "The FMI defines the type of failure detected in the subsystem identified by an SPN.";
CM_ BO_ 2562850558 "Diagnostic Readiness 2";
CM_ SG_ 2562850558 TimeSinceDTCsCleared "Time accumulated since DTCs were cleared (via an external test equipment or possibly, a battery disconnect) (SPN=?).";
CM_ SG_ 2562850558 MinutesRunByEngineMILActivated "Accumulated count (in minutes) while the MIL is activated (on) (SPN=?).";
CM_ SG_ 2562850558 DistanceSinceDTCsCleared "Distance accumulated since DTCs were cleared (SPN=?).";
CM_ SG_ 2562850558 DistanceWhileMILisActivated "The kilometers accumulated while the MIL is activated (SPN 3060).";
CM_ BO_ 2562916094 "Monitor Performance Ratio";
CM_ SG_ 2562916094 ApplSysMonitorDenominator "The number of times a vehicle has been operated that constitutes a driving cycle where this Applicable System Monitor could be operated per regulatory requirements (SPN 3068).";
CM_ SG_ 2562916094 ApplSysMonitorNumerator "The number of times a vehicle has been operated such that all conditions necessary for the Applicable System Monitor to detect a malfunction have been encountered (SPN 3067).";
CM_ SG_ 2562916094 SPNofApplSysMonitor "Contain the SPN of the system monitor for which Monitor ratio is being reported (SPN 3066).";
CM_ SG_ 2562916094 OBDMonitoringCondEncountered "Displays the number of times that the vehicle has been operated in the specified OBD monitoring conditions (SPN 3049).";
CM_ SG_ 2562916094 IgnitionCycleCounter "A single counter that defines the number of ignition cycles (SPN 3048).";
CM_ BO_ 2566835198 "Previously Active Diagnostic Trouble Codes";
CM_ SG_ 2566835198 MalfunctionIndicatorLampStatus "A lamp used to relay only emissions-related trouble code information.";
CM_ SG_ 2566835198 RedStopLampStatus "This lamp is uesed to relay trouble code information that is of a severe enought condition that it warrants stopping the vehicle.";
CM_ SG_ 2566835198 AmberWarningLampStatus "This lamp is used to relay trouble code information that is reporting a problem with the vehicle system but the vehicle need
not be immediately stopped.";
CM_ SG_ 2566835198 ProtectLampStatus "This lamp is used to relay trouble code informatio that is reporting a problem with a vehicle system that is most
probably not electronic subsystem related.";
CM_ SG_ 2566835198 FlashRedStopLamp "This parameter provides the capability to flash the RSL (SPN 3039).";
CM_ SG_ 2566835198 FlashProtectLamp "This parameter provides the capability to flash the engine protect lamp (SPN 3041).";
CM_ SG_ 2566835198 FlashMalfuncIndicatorLamp "This parameter provides the capability to flash the MIL (SPN 3038).";
CM_ SG_ 2566835198 FlashAmberWarningLamp "This parameter provides the capability to flash the AWL (SPN 3040). ";
CM_ BO_ 2564030206 "Calibration Information";
CM_ BO_ 2564226814 "Boot Load Data";
CM_ BO_ 2564292350 "Binary Data Transfer";
CM_ SG_ 2564292350 NumberOfOccurance "Number of occurance of raw binary data";
CM_ BO_ 2564357886 "Memory Access Response";
CM_ SG_ 2564357886 ErrorIndicator "Error Indicator/EDC Parameter";
CM_ BO_ 2564423422 "Memory Access Request";
CM_ SG_ 2564423422 KeyOrUserLevel "Key/User Level";
CM_ SG_ 2564423422 NumberRequested "Length/Number Requested";
CM_ SG_ 2564423422 NumberRequestedHigh "Length/Number Requested";
CM_ BO_ 2564816638 "Stop-Start Broadcast";
CM_ SG_ 2564816638 HoldSignal "Indicator to all nodes that the communication ports that have been acted upon by the 'Stop start broadcast'
PGN are remaining in the modified state.";
CM_ SG_ 2564816638 J1939Network3 "Identifies the action to be performed on the SAE J1939 Network #3.";
CM_ SG_ 2564816638 J1939Network2 "Identifies the action to be performed on the SAE J1939 Network #2.";
CM_ SG_ 2564816638 ISO9141 "Identifies the action to be performed on the ISO9141 communications port.";
CM_ SG_ 2564816638 SAE_J1850 "Identifies the action to be performed on the SAE J1850 communications port.";
CM_ SG_ 2564816638 ManufacturerSpecificPort "Identifies the action to be performed on 'Other, manufacturer specific port' communications port.";
CM_ SG_ 2564816638 CurrentDataLink "Identifies the action to be performed on the communications port that this parameter was received.";
CM_ SG_ 2564816638 SAE_J1587 "Identifies the action to be performed on the SAE J1587 communications port.";
CM_ SG_ 2564816638 SAE_J1922 "Identifies the action to be performed on the SAE J1922 communications port.";
CM_ SG_ 2564816638 J1939Network1 "Identifies the action to be performed on the SAE J1939 Network #1, Primary vehicle communications port.";
CM_ BO_ 2566837502 "Emission-Related MIL-On Diagnostic Trouble Codes";
CM_ SG_ 2566837502 FlashRedStopLamp "This parameter provides the capability to flash the RSL (SPN 3039).";
CM_ SG_ 2566837502 FlashProtectLamp "This parameter provides the capability to flash the engine protect lamp (SPN 3041).";
CM_ SG_ 2566837502 MalfunctionIndicatorLampStatus "A lamp used to relay only emissions-related trouble code information.";
CM_ SG_ 2566837502 RedStopLampStatus "This lamp is uesed to relay trouble code information that is of a severe enought condition that it warrants stopping the vehicle.";
CM_ SG_ 2566837502 AmberWarningLampStatus "This lamp is used to relay trouble code information that is reporting a problem with the vehicle system but the vehicle need
not be immediately stopped.";
CM_ SG_ 2566837502 ProtectLampStatus "This lamp is used to relay trouble code informatio that is reporting a problem with a vehicle system that is most
probably not electronic subsystem related.";
CM_ SG_ 2566837502 FlashMalfuncIndicatorLamp "This parameter provides the capability to flash the MIL (SPN 3038).";
CM_ SG_ 2566837502 FlashAmberWarningLamp "This parameter provides the capability to flash the AWL (SPN 3040). ";
CM_ BO_ 2566837246 "Diagnostic Data Clear/Reset for Active DTCs";
CM_ BO_ 2566836990 "Non-Continuously Monitored Systems Test Identifiers Support";
CM_ SG_ 2566836990 TestIdentifierSupported "Indicates the test identifiers that the controller supports.";
CM_ BO_ 2566834942 "Active Diagnostic Trouble Codes. DM1 provides diagnostic lamp status and diagnostic trouble codes (DTCs). Together, the lamp and DTC information convey the diagnostic condition of the transmitting electronic component to other components on the network.";
CM_ SG_ 2566834942 FlashRedStopLamp "This parameter provides the capability to flash the RSL (SPN 3039).";
CM_ SG_ 2566834942 FlashProtectLamp "This parameter provides the capability to flash the engine protect lamp (SPN 3041).";
CM_ SG_ 2566834942 FlashMalfuncIndicatorLamp "This parameter provides the capability to flash the MIL (SPN 3038).";
CM_ SG_ 2566834942 FlashAmberWarningLamp "This parameter provides the capability to flash the AWL (SPN 3040). ";
CM_ SG_ 2566834942 MalfunctionIndicatorLampStatus "A lamp used to relay only emissions-related trouble code information.";
CM_ SG_ 2566834942 AmberWarningLampStatus "This lamp is used to relay trouble code information that is reporting a problem with the vehicle system but the vehicle need
not be immediately stopped.";
CM_ SG_ 2566834942 RedStopLampStatus "This lamp is uesed to relay trouble code information that is of a severe enought condition that it warrants stopping the vehicle.";
CM_ SG_ 2566834942 ProtectLampStatus "This lamp is used to relay trouble code informatio that is reporting a problem with a vehicle system that is most
probably not electronic subsystem related.";
CM_ BO_ 2566739198 "DTCs - C, Previously Active";
CM_ SG_ 2566739198 FlashRedStopLamp "This parameter provides the capability to flash the RSL (SPN 3039).";
CM_ SG_ 2566739198 FlashProtectLamp "This parameter provides the capability to flash the engine protect lamp (SPN 3041).";
CM_ SG_ 2566739198 FlashMalfuncIndicatorLamp "This parameter provides the capability to flash the MIL (SPN 3038).";
CM_ SG_ 2566739198 FlashAmberWarningLamp "This parameter provides the capability to flash the AWL (SPN 3040). ";
CM_ SG_ 2566739198 MalfunctionIndicatorLampStatus "A lamp used to relay only emissions-related trouble code information.";
CM_ SG_ 2566739198 AmberWarningLampStatus "This lamp is used to relay trouble code information that is reporting a problem with the vehicle system but the vehicle need
not be immediately stopped.";
CM_ SG_ 2566739198 RedStopLampStatus "This lamp is uesed to relay trouble code information that is of a severe enought condition that it warrants stopping the vehicle.";
CM_ SG_ 2566739198 ProtectLampStatus "This lamp is used to relay trouble code informatio that is reporting a problem with a vehicle system that is most
probably not electronic subsystem related.";
CM_ BO_ 2566739454 "DTCs - C, Confirmed and Active";
CM_ SG_ 2566739454 FlashRedStopLamp "This parameter provides the capability to flash the RSL (SPN 3039).";
CM_ SG_ 2566739454 FlashProtectLamp "This parameter provides the capability to flash the engine protect lamp (SPN 3041).";
CM_ SG_ 2566739454 FlashMalfuncIndicatorLamp "This parameter provides the capability to flash the MIL (SPN 3038).";
CM_ SG_ 2566739454 FlashAmberWarningLamp "This parameter provides the capability to flash the AWL (SPN 3040). ";
CM_ SG_ 2566739454 MalfunctionIndicatorLampStatus "A lamp used to relay only emissions-related trouble code information.";
CM_ SG_ 2566739454 AmberWarningLampStatus "This lamp is used to relay trouble code information that is reporting a problem with the vehicle system but the vehicle need
not be immediately stopped.";
CM_ SG_ 2566739454 RedStopLampStatus "This lamp is uesed to relay trouble code information that is of a severe enought condition that it warrants stopping the vehicle.";
CM_ SG_ 2566739454 ProtectLampStatus "This lamp is used to relay trouble code informatio that is reporting a problem with a vehicle system that is most
probably not electronic subsystem related.";
BA_DEF_ SG_  "SigType" ENUM  "Default","Range","RangeSigned","ASCII","Discrete","Control","ReferencePGN","DTC","StringDelimiter","StringLength","StringLengthControl";
BA_DEF_ SG_  "GenSigStartValue" INT 0 10000;
BA_DEF_ SG_  "GenSigSendType" ENUM  "Cyclic","OnWrite","reserved","OnChange","reserved","reserved","reserved","NoSigSendType";
BA_DEF_ SG_  "GenSigILSupport" ENUM  "Yes","No";
BA_DEF_ SG_  "GenSigEVName" STRING ;
BA_DEF_ SG_  "SPN" INT 0 524287;
BA_DEF_ BO_  "GenMsgILSupport" ENUM  "Yes","No";
BA_DEF_ BO_  "GenMsgRequestable" INT 0 1;
BA_DEF_ BO_  "GenMsgSendType" ENUM  "cyclic","reserved","cyclicIfActive","reserved","reserved","reserved","reserved","reserved","noMsgSendType";
BA_DEF_ BO_  "VFrameFormat" ENUM  "StandardCAN","ExtendedCAN","reserved","J1939PG";
BA_DEF_ BU_  "NmStationAddress" INT 0 255;
BA_DEF_  "DatabaseVersion" STRING ;
BA_DEF_  "BusType" STRING ;
BA_DEF_  "ProtocolType" STRING ;
BA_DEF_ SG_  "SystemSignalLongSymbol" STRING ;
BA_DEF_DEF_  "SigType" "Default";
BA_DEF_DEF_  "GenSigStartValue" 0;
BA_DEF_DEF_  "GenSigSendType" "NoSigSendType";
BA_DEF_DEF_  "GenSigILSupport" "Yes";
BA_DEF_DEF_  "GenSigEVName" "Env@Nodename_@Signame";
BA_DEF_DEF_  "SPN" 0;
BA_DEF_DEF_  "GenMsgILSupport" "Yes";
BA_DEF_DEF_  "GenMsgRequestable" 1;
BA_DEF_DEF_  "GenMsgSendType" "noMsgSendType";
BA_DEF_DEF_  "VFrameFormat" "J1939PG";
BA_DEF_DEF_  "NmStationAddress" 254;
BA_DEF_DEF_  "DatabaseVersion" "";
BA_DEF_DEF_  "BusType" "";
BA_DEF_DEF_  "ProtocolType" "";
BA_DEF_DEF_  "SystemSignalLongSymbol" "";
BA_ "ProtocolType" "J1939";
BA_ "BusType" "CAN";
BA_ "DatabaseVersion" "2.1";
BA_ "SPN" SG_ 2564095742 SecurityEntityLengthHigh 1596;
BA_ "SPN" SG_ 2564095742 SecurityEntityType 1479;
BA_ "SPN" SG_ 2564095742 SecurityEntityLength 1596;
BA_ "SPN" SG_ 2566742270 FailureSpecificB1Counter 4147;
BA_ "SigType" SG_ 2566742270 FailureSpecificB1Counter 1;
BA_ "SPN" SG_ 2566742270 DM40_01FMI 1215;
BA_ "SPN" SG_ 2566742270 DM40_01SPN_High 1214;
BA_ "SPN" SG_ 2566742270 DM40_01SPN 1214;
BA_ "SPN" SG_ 2566742526 SysGreatestB1Counter 4146;
BA_ "SigType" SG_ 2566742526 SysGreatestB1Counter 1;
BA_ "SPN" SG_ 2566742526 SysCumulativeContinuousMITime 4145;
BA_ "SigType" SG_ 2566742526 SysCumulativeContinuousMITime 1;
BA_ "SPN" SG_ 2566742782 RegulationDescription 4144;
BA_ "SigType" SG_ 2566742782 RegulationDescription 8;
BA_ "SPN" SG_ 2566743038 SysIncompleteMonitorCount 4143;
BA_ "SigType" SG_ 2566743038 SysIncompleteMonitorCount 1;
BA_ "SPN" SG_ 2566743038 SysMalIndActivationMode 4142;
BA_ "SPN" SG_ 2566743038 SysMalIndDisplayStrategy 4141;
BA_ "SigType" SG_ 2566743038 SysMalIndDisplayStrategy 4;
BA_ "SPN" SG_ 2566743038 SysContinuousMalfunctionInd 4140;
BA_ "SigType" SG_ 2566743038 SysContinuousMalfunctionInd 4;
BA_ "SPN" SG_ 2566743038 SysNonRoadworthyCompCount 4139;
BA_ "SigType" SG_ 2566743038 SysNonRoadworthyCompCount 1;
BA_ "SPN" SG_ 2566743294 VehicleCurrentMIAccumTime 4138;
BA_ "SigType" SG_ 2566743294 VehicleCurrentMIAccumTime 1;
BA_ "SPN" SG_ 2566743294 VehicleIncompleteMonitorCount 4137;
BA_ "SigType" SG_ 2566743294 VehicleIncompleteMonitorCount 1;
BA_ "SPN" SG_ 2566743294 VehicleMalfunctionIndActMode 4136;
BA_ "SigType" SG_ 2566743294 VehicleMalfunctionIndActMode 4;
BA_ "SPN" SG_ 2566743294 VehicleMalfunctionIndStrategy 4135;
BA_ "SigType" SG_ 2566743294 VehicleMalfunctionIndStrategy 4;
BA_ "SPN" SG_ 2566743294 VehicleContinuousMalfunctionInd 4134;
BA_ "SigType" SG_ 2566743294 VehicleContinuousMalfunctionInd 4;
BA_ "SPN" SG_ 2566743294 VehicleNonRoadworthyCompCount 4133;
BA_ "SigType" SG_ 2566743294 VehicleNonRoadworthyCompCount 1;
BA_ "SPN" SG_ 2560687870 PMNTEDeficiencyAreaStatus 4132;
BA_ "SigType" SG_ 2560687870 PMNTEDeficiencyAreaStatus 4;
BA_ "SPN" SG_ 2560687870 MnfcPMNTECarveOutAreaStatus 4131;
BA_ "SigType" SG_ 2560687870 MnfcPMNTECarveOutAreaStatus 4;
BA_ "SPN" SG_ 2560687870 PMNTEControlAreaStatus 4130;
BA_ "SigType" SG_ 2560687870 PMNTEControlAreaStatus 4;
BA_ "SPN" SG_ 2560687870 NOxNTEDeficiencyAreaStatus 4129;
BA_ "SigType" SG_ 2560687870 NOxNTEDeficiencyAreaStatus 4;
BA_ "SPN" SG_ 2560687870 MnfcNOxNTECarveOutAreaStatus 4128;
BA_ "SigType" SG_ 2560687870 MnfcNOxNTECarveOutAreaStatus 4;
BA_ "SPN" SG_ 2560687870 NOxNTEControlAreaStatus 4127;
BA_ "SigType" SG_ 2560687870 NOxNTEControlAreaStatus 4;
BA_ "SPN" SG_ 2292317950 AECDEngineHours1Timer2 4126;
BA_ "SigType" SG_ 2292317950 AECDEngineHours1Timer2 1;
BA_ "SPN" SG_ 2292317950 AECDEngineHours1Timer1 4125;
BA_ "SigType" SG_ 2292317950 AECDEngineHours1Timer1 1;
BA_ "SPN" SG_ 2292317950 AECDNumber1 4124;
BA_ "SigType" SG_ 2292317950 AECDNumber1 1;
BA_ "SPN" SG_ 2560884478 DTCWarnLampSupportStatus 4115;
BA_ "SigType" SG_ 2560884478 DTCWarnLampSupportStatus 4;
BA_ "SPN" SG_ 2560884478 DTCWarnLampSupportFlash 4119;
BA_ "SigType" SG_ 2560884478 DTCWarnLampSupportFlash 4;
BA_ "SPN" SG_ 2560884478 DTCStopLampSupportStatus 4114;
BA_ "SigType" SG_ 2560884478 DTCStopLampSupportStatus 4;
BA_ "SPN" SG_ 2560884478 DTCStopLampSupportFlash 4118;
BA_ "SigType" SG_ 2560884478 DTCStopLampSupportFlash 4;
BA_ "SPN" SG_ 2560884478 DTCProtectLampSupportStatus 4116;
BA_ "SigType" SG_ 2560884478 DTCProtectLampSupportStatus 4;
BA_ "SPN" SG_ 2560884478 DTCProtectLampSupportFlash 4120;
BA_ "SigType" SG_ 2560884478 DTCProtectLampSupportFlash 4;
BA_ "SPN" SG_ 2560884478 DTCMilSupportStatus 4113;
BA_ "SPN" SG_ 2560884478 DTCMilSupportFlash 4117;
BA_ "SPN" SG_ 2560950014 TestLimitMinimum 4112;
BA_ "SigType" SG_ 2560950014 TestLimitMinimum 1;
BA_ "SPN" SG_ 2560950014 TestLimitMaximum 4111;
BA_ "SigType" SG_ 2560950014 TestLimitMaximum 1;
BA_ "SPN" SG_ 2560950014 TestValue 4110;
BA_ "SigType" SG_ 2560950014 TestValue 1;
BA_ "SPN" SG_ 2560950014 SlotId 4109;
BA_ "SigType" SG_ 2560950014 SlotId 1;
BA_ "SPN" SG_ 2560950014 DM30_01FMI 1215;
BA_ "SPN" SG_ 2560950014 DM30_01SPN_High 1214;
BA_ "SPN" SG_ 2560950014 DM30_01SPN 1214;
BA_ "SPN" SG_ 2566836478 TestLimitMinimum 1228;
BA_ "SigType" SG_ 2566836478 TestLimitMinimum 1;
BA_ "SPN" SG_ 2566836478 TestLimitMaximum 1227;
BA_ "SigType" SG_ 2566836478 TestLimitMaximum 1;
BA_ "SPN" SG_ 2566836478 TestValue 1226;
BA_ "SigType" SG_ 2566836478 TestValue 1;
BA_ "SPN" SG_ 2566836478 TestType 1225;
BA_ "GenSigStartValue" SG_ 2566836478 TestType 1;
BA_ "SigType" SG_ 2566836478 TestType 1;
BA_ "SPN" SG_ 2566836478 TestIdentifier 1224;
BA_ "GenSigStartValue" SG_ 2566836478 TestIdentifier 1;
BA_ "SigType" SG_ 2566836478 TestIdentifier 1;
BA_ "SPN" SG_ 2565078782 DM07_01SPN_High 1214;
BA_ "SPN" SG_ 2565078782 DM07_01SPN 1214;
BA_ "SPN" SG_ 2565078782 TestIdentifier 1224;
BA_ "GenSigStartValue" SG_ 2565078782 TestIdentifier 1;
BA_ "SigType" SG_ 2565078782 TestIdentifier 1;
BA_ "SPN" SG_ 2565078782 DM07_01FMI 1215;
BA_ "SPN" SG_ 2566836222 FlashRedStopLamp 3039;
BA_ "SigType" SG_ 2566836222 FlashRedStopLamp 4;
BA_ "SPN" SG_ 2566836222 FlashProtectLamp 3041;
BA_ "SigType" SG_ 2566836222 FlashProtectLamp 4;
BA_ "SPN" SG_ 2566836222 FlashMalfuncIndicatorLamp 3038;
BA_ "SigType" SG_ 2566836222 FlashMalfuncIndicatorLamp 4;
BA_ "SPN" SG_ 2566836222 FlashAmberWarningLamp 3040;
BA_ "SigType" SG_ 2566836222 FlashAmberWarningLamp 4;
BA_ "SPN" SG_ 2566836222 MalfunctionIndicatorLampStatus 1213;
BA_ "SigType" SG_ 2566836222 MalfunctionIndicatorLampStatus 4;
BA_ "SPN" SG_ 2566836222 RedStopLampStatus 623;
BA_ "SigType" SG_ 2566836222 RedStopLampStatus 4;
BA_ "SPN" SG_ 2566836222 AmberWarningLampStatus 624;
BA_ "SigType" SG_ 2566836222 AmberWarningLampStatus 4;
BA_ "SPN" SG_ 2566836222 ProtectLampStatus 987;
BA_ "SigType" SG_ 2566836222 ProtectLampStatus 4;
BA_ "SystemSignalLongSymbol" SG_ 2566835966 NOxConvertingCatalystAdsorberSta "NOxConvertingCatalystAdsorberStatus";
BA_ "SystemSignalLongSymbol" SG_ 2566835966 BoostPressureControlSystemSuppor "BoostPressureControlSystemSupport";
BA_ "SystemSignalLongSymbol" SG_ 2566835966 NOxConvertingCatalystAdsorberSup "NOxConvertingCatalystAdsorberSupport";
BA_ "SPN" SG_ 2566835966 MisfireMonitoringSupport 1221;
BA_ "SPN" SG_ 2566835966 OBDCompliance 1220;
BA_ "SigType" SG_ 2566835966 OBDCompliance 1;
BA_ "SPN" SG_ 2566835966 PreviouslyActiveTroubleCodeCount 1219;
BA_ "SigType" SG_ 2566835966 PreviouslyActiveTroubleCodeCount 1;
BA_ "SPN" SG_ 2566835966 ActiveTroubleCodeCount 1218;
BA_ "SigType" SG_ 2566835966 ActiveTroubleCodeCount 1;
BA_ "SPN" SG_ 2566835966 SecondAirSystemMonStatus 1223;
BA_ "SPN" SG_ 2566835966 EvaporativeSystemMonStatus 1223;
BA_ "SPN" SG_ 2566835966 ACSystemRefrigerantMonStatus 1223;
BA_ "SPN" SG_ 2566835966 OxygenSensorHeaterMonStatus 1223;
BA_ "SPN" SG_ 2566835966 OxygenSensorMonStatus 1223;
BA_ "SPN" SG_ 2566835966 EGRSystemMonitoringStatus 1223;
BA_ "SPN" SG_ 2566835966 CatalystMonStatus 1223;
BA_ "SPN" SG_ 2566835966 ColdStartAidSystemMonStatus 1223;
BA_ "SPN" SG_ 2566835966 HeatedCatalystMonStatus 1223;
BA_ "SPN" SG_ 2566835966 CatalystMonSupp 1222;
BA_ "SPN" SG_ 2566835966 ColdStartAidSystemMonSupp 1222;
BA_ "SPN" SG_ 2566835966 HeatedCatalystMonSupp 1222;
BA_ "SPN" SG_ 2566835966 EvaporativeSystemMonSupp 1222;
BA_ "SPN" SG_ 2566835966 SecondAirSystemMonSupp 1222;
BA_ "SPN" SG_ 2566835966 ACSystemRefrigerantMonSupp 1222;
BA_ "SPN" SG_ 2566835966 OxygenSensorMonSupp 1222;
BA_ "SPN" SG_ 2566835966 OxygenSensorHeaterMonSupp 1222;
BA_ "SPN" SG_ 2566835966 EGRSystemMonitoringSupp 1222;
BA_ "SPN" SG_ 2566835966 MisfireMonitoringStatus 1221;
BA_ "SPN" SG_ 2566835966 ComprehensiveCompMonStatus 1221;
BA_ "SPN" SG_ 2566835966 FuelSystemMonitoringStatus 1221;
BA_ "SPN" SG_ 2566835966 ComprehensiveComponentMonSupp 1221;
BA_ "SPN" SG_ 2566835966 FuelSystemMonitoringSupport 1221;
BA_ "SPN" SG_ 2566835710 EngIntakeManifold1Press 102;
BA_ "SigType" SG_ 2566835710 EngIntakeManifold1Press 1;
BA_ "SPN" SG_ 2566835710 FreezeFrameLength 1217;
BA_ "SPN" SG_ 2566835710 EngSpeed 190;
BA_ "SigType" SG_ 2566835710 EngSpeed 1;
BA_ "SPN" SG_ 2566835710 EngTorqueMode 899;
BA_ "SigType" SG_ 2566835710 EngTorqueMode 4;
BA_ "SPN" SG_ 2566835710 WheelBasedVehicleSpeed 84;
BA_ "SigType" SG_ 2566835710 WheelBasedVehicleSpeed 1;
BA_ "SPN" SG_ 2566835710 EngPercentLoadAtCurrentSpeed 92;
BA_ "SigType" SG_ 2566835710 EngPercentLoadAtCurrentSpeed 1;
BA_ "SPN" SG_ 2566835710 EngineCoolantTemperature 110;
BA_ "SigType" SG_ 2566835710 EngineCoolantTemperature 1;
BA_ "SPN" SG_ 2566764542 ExpandedFreezeFrameLength 3149;
BA_ "SPN" SG_ 2566764286 SPNSupported1High 3146;
BA_ "SPN" SG_ 2566764286 SPNSupported3High 3146;
BA_ "SPN" SG_ 2566764286 SPNSupported2High 3146;
BA_ "SPN" SG_ 2566764286 SPNSupported3 3146;
BA_ "SPN" SG_ 2566764286 SPNSupported2 3146;
BA_ "SPN" SG_ 2566764286 SPNDataLength3 3148;
BA_ "SPN" SG_ 2566764286 SPNDataLength2 3148;
BA_ "SPN" SG_ 2566764286 SPNDataLength1 3148;
BA_ "SPN" SG_ 2566764286 SPNSupported1 3146;
BA_ "SPN" SG_ 2566764030 FlashRedStopLamp 3039;
BA_ "SigType" SG_ 2566764030 FlashRedStopLamp 4;
BA_ "SPN" SG_ 2566764030 FlashProtectLamp 3041;
BA_ "SigType" SG_ 2566764030 FlashProtectLamp 4;
BA_ "SPN" SG_ 2566764030 FlashMalfuncIndicatorLamp 3038;
BA_ "SigType" SG_ 2566764030 FlashMalfuncIndicatorLamp 4;
BA_ "SPN" SG_ 2566764030 FlashAmberWarningLamp 3040;
BA_ "SigType" SG_ 2566764030 FlashAmberWarningLamp 4;
BA_ "SPN" SG_ 2566764030 MalfunctionIndicatorLampStatus 1213;
BA_ "SigType" SG_ 2566764030 MalfunctionIndicatorLampStatus 4;
BA_ "SPN" SG_ 2566764030 RedStopLampStatus 623;
BA_ "SigType" SG_ 2566764030 RedStopLampStatus 4;
BA_ "SPN" SG_ 2566764030 AmberWarningLampStatus 624;
BA_ "SigType" SG_ 2566764030 AmberWarningLampStatus 4;
BA_ "SPN" SG_ 2566764030 ProtectLampStatus 987;
BA_ "SigType" SG_ 2566764030 ProtectLampStatus 4;
BA_ "SPN" SG_ 2562981630 IndividualDTCClearControlByte 3034;
BA_ "SPN" SG_ 2562981630 CtrlByteIndicIndividualDTCClear 3035;
BA_ "SPN" SG_ 2562981630 DM22_01SPN 1214;
BA_ "SPN" SG_ 2562981630 DM22_01SPN_High 1214;
BA_ "SPN" SG_ 2562981630 DM22_01FMI 1215;
BA_ "SPN" SG_ 2562850558 TimeSinceDTCsCleared 3145;
BA_ "SigType" SG_ 2562850558 TimeSinceDTCsCleared 1;
BA_ "SPN" SG_ 2562850558 MinutesRunByEngineMILActivated 3144;
BA_ "SigType" SG_ 2562850558 MinutesRunByEngineMILActivated 1;
BA_ "SPN" SG_ 2562850558 DistanceSinceDTCsCleared 3143;
BA_ "SigType" SG_ 2562850558 DistanceSinceDTCsCleared 1;
BA_ "SPN" SG_ 2562850558 DistanceWhileMILisActivated 3069;
BA_ "SigType" SG_ 2562850558 DistanceWhileMILisActivated 1;
BA_ "SPN" SG_ 2562916094 ApplSysMonitorDenominator 3068;
BA_ "SigType" SG_ 2562916094 ApplSysMonitorDenominator 1;
BA_ "SPN" SG_ 2562916094 ApplSysMonitorNumerator 3067;
BA_ "SigType" SG_ 2562916094 ApplSysMonitorNumerator 1;
BA_ "SPN" SG_ 2562916094 SPNofApplSysMonitor 3066;
BA_ "SigType" SG_ 2562916094 SPNofApplSysMonitor 1;
BA_ "SPN" SG_ 2562916094 OBDMonitoringCondEncountered 3049;
BA_ "SigType" SG_ 2562916094 OBDMonitoringCondEncountered 1;
BA_ "SPN" SG_ 2562916094 IgnitionCycleCounter 3048;
BA_ "SigType" SG_ 2562916094 IgnitionCycleCounter 1;
BA_ "SPN" SG_ 2566835198 MalfunctionIndicatorLampStatus 1213;
BA_ "SigType" SG_ 2566835198 MalfunctionIndicatorLampStatus 4;
BA_ "SPN" SG_ 2566835198 RedStopLampStatus 623;
BA_ "SigType" SG_ 2566835198 RedStopLampStatus 4;
BA_ "SPN" SG_ 2566835198 AmberWarningLampStatus 624;
BA_ "SigType" SG_ 2566835198 AmberWarningLampStatus 4;
BA_ "SPN" SG_ 2566835198 ProtectLampStatus 987;
BA_ "SigType" SG_ 2566835198 ProtectLampStatus 4;
BA_ "SPN" SG_ 2566835198 FlashRedStopLamp 3039;
BA_ "SigType" SG_ 2566835198 FlashRedStopLamp 4;
BA_ "SPN" SG_ 2566835198 FlashProtectLamp 3041;
BA_ "SigType" SG_ 2566835198 FlashProtectLamp 4;
BA_ "SPN" SG_ 2566835198 FlashMalfuncIndicatorLamp 3038;
BA_ "SigType" SG_ 2566835198 FlashMalfuncIndicatorLamp 4;
BA_ "SPN" SG_ 2566835198 FlashAmberWarningLamp 3040;
BA_ "SigType" SG_ 2566835198 FlashAmberWarningLamp 4;
BA_ "SPN" SG_ 2564030206 CalibrationID4 1635;
BA_ "SPN" SG_ 2564030206 CalibrationID3 1635;
BA_ "SPN" SG_ 2564030206 CalibrationID2 1635;
BA_ "SPN" SG_ 2564030206 CalibrationID1 1635;
BA_ "SPN" SG_ 2564030206 CalibrationVerificationNumber 1634;
BA_ "SigType" SG_ 2564030206 CalibrationVerificationNumber 1;
BA_ "SPN" SG_ 2564423422 KeyOrUserLevel 1645;
BA_ "SPN" SG_ 2564423422 PointerExtension 1643;
BA_ "SPN" SG_ 2564423422 Pointer 1644;
BA_ "SPN" SG_ 2564423422 Command 1642;
BA_ "SPN" SG_ 2564423422 PointerType 1641;
BA_ "SPN" SG_ 2564423422 NumberRequested 1640;
BA_ "SPN" SG_ 2564423422 NumberRequestedHigh 1640;
BA_ "SPN" SG_ 2564816638 HoldSignal 1236;
BA_ "SPN" SG_ 2564816638 J1939Network3 1235;
BA_ "SigType" SG_ 2564816638 J1939Network3 4;
BA_ "SPN" SG_ 2564816638 J1939Network2 1231;
BA_ "SigType" SG_ 2564816638 J1939Network2 4;
BA_ "SPN" SG_ 2564816638 ISO9141 1232;
BA_ "SigType" SG_ 2564816638 ISO9141 4;
BA_ "SPN" SG_ 2564816638 SAE_J1850 1233;
BA_ "SigType" SG_ 2564816638 SAE_J1850 4;
BA_ "SPN" SG_ 2564816638 ManufacturerSpecificPort 1234;
BA_ "SigType" SG_ 2564816638 ManufacturerSpecificPort 4;
BA_ "SPN" SG_ 2564816638 CurrentDataLink 1230;
BA_ "SigType" SG_ 2564816638 CurrentDataLink 4;
BA_ "SPN" SG_ 2564816638 SAE_J1587 608;
BA_ "SigType" SG_ 2564816638 SAE_J1587 4;
BA_ "SPN" SG_ 2564816638 SAE_J1922 622;
BA_ "SigType" SG_ 2564816638 SAE_J1922 4;
BA_ "SPN" SG_ 2564816638 J1939Network1 639;
BA_ "SigType" SG_ 2564816638 J1939Network1 4;
BA_ "SPN" SG_ 2564816638 SuspendSignal 2618;
BA_ "SPN" SG_ 2564816638 SuspendDuration 2619;
BA_ "SPN" SG_ 2566837502 FlashRedStopLamp 3039;
BA_ "SigType" SG_ 2566837502 FlashRedStopLamp 4;
BA_ "SPN" SG_ 2566837502 FlashProtectLamp 3041;
BA_ "SigType" SG_ 2566837502 FlashProtectLamp 4;
BA_ "SPN" SG_ 2566837502 MalfunctionIndicatorLampStatus 1213;
BA_ "SigType" SG_ 2566837502 MalfunctionIndicatorLampStatus 4;
BA_ "SPN" SG_ 2566837502 RedStopLampStatus 623;
BA_ "SigType" SG_ 2566837502 RedStopLampStatus 4;
BA_ "SPN" SG_ 2566837502 AmberWarningLampStatus 624;
BA_ "SigType" SG_ 2566837502 AmberWarningLampStatus 4;
BA_ "SPN" SG_ 2566837502 ProtectLampStatus 987;
BA_ "SigType" SG_ 2566837502 ProtectLampStatus 4;
BA_ "SPN" SG_ 2566837502 FlashMalfuncIndicatorLamp 3038;
BA_ "SigType" SG_ 2566837502 FlashMalfuncIndicatorLamp 4;
BA_ "SPN" SG_ 2566837502 FlashAmberWarningLamp 3040;
BA_ "SigType" SG_ 2566837502 FlashAmberWarningLamp 4;
BA_ "SPN" SG_ 2566836990 TestIdentifierSupported 1229;
BA_ "GenSigStartValue" SG_ 2566836990 TestIdentifierSupported 1;
BA_ "SigType" SG_ 2566836990 TestIdentifierSupported 1;
BA_ "SPN" SG_ 2566834942 FlashRedStopLamp 3039;
BA_ "SigType" SG_ 2566834942 FlashRedStopLamp 4;
BA_ "SPN" SG_ 2566834942 FlashProtectLamp 3041;
BA_ "SigType" SG_ 2566834942 FlashProtectLamp 4;
BA_ "SPN" SG_ 2566834942 FlashMalfuncIndicatorLamp 3038;
BA_ "SigType" SG_ 2566834942 FlashMalfuncIndicatorLamp 4;
BA_ "SPN" SG_ 2566834942 FlashAmberWarningLamp 3040;
BA_ "SigType" SG_ 2566834942 FlashAmberWarningLamp 4;
BA_ "SPN" SG_ 2566834942 MalfunctionIndicatorLampStatus 1213;
BA_ "SigType" SG_ 2566834942 MalfunctionIndicatorLampStatus 4;
BA_ "SPN" SG_ 2566834942 AmberWarningLampStatus 624;
BA_ "SigType" SG_ 2566834942 AmberWarningLampStatus 4;
BA_ "SPN" SG_ 2566834942 RedStopLampStatus 623;
BA_ "SigType" SG_ 2566834942 RedStopLampStatus 4;
BA_ "SPN" SG_ 2566834942 ProtectLampStatus 987;
BA_ "SigType" SG_ 2566834942 ProtectLampStatus 4;
BA_ "SPN" SG_ 2566739198 FlashRedStopLamp 3039;
BA_ "SigType" SG_ 2566739198 FlashRedStopLamp 4;
BA_ "SPN" SG_ 2566739198 FlashProtectLamp 3041;
BA_ "SigType" SG_ 2566739198 FlashProtectLamp 4;
BA_ "SPN" SG_ 2566739198 FlashMalfuncIndicatorLamp 3038;
BA_ "SigType" SG_ 2566739198 FlashMalfuncIndicatorLamp 4;
BA_ "SPN" SG_ 2566739198 FlashAmberWarningLamp 3040;
BA_ "SigType" SG_ 2566739198 FlashAmberWarningLamp 4;
BA_ "SPN" SG_ 2566739198 MalfunctionIndicatorLampStatus 1213;
BA_ "SigType" SG_ 2566739198 MalfunctionIndicatorLampStatus 4;
BA_ "SPN" SG_ 2566739198 AmberWarningLampStatus 624;
BA_ "SigType" SG_ 2566739198 AmberWarningLampStatus 4;
BA_ "SPN" SG_ 2566739198 RedStopLampStatus 623;
BA_ "SigType" SG_ 2566739198 RedStopLampStatus 4;
BA_ "SPN" SG_ 2566739198 ProtectLampStatus 987;
BA_ "SigType" SG_ 2566739198 ProtectLampStatus 4;
BA_ "SPN" SG_ 2566739454 FlashRedStopLamp 3039;
BA_ "SigType" SG_ 2566739454 FlashRedStopLamp 4;
BA_ "SPN" SG_ 2566739454 FlashProtectLamp 3041;
BA_ "SigType" SG_ 2566739454 FlashProtectLamp 4;
BA_ "SPN" SG_ 2566739454 FlashMalfuncIndicatorLamp 3038;
BA_ "SigType" SG_ 2566739454 FlashMalfuncIndicatorLamp 4;
BA_ "SPN" SG_ 2566739454 FlashAmberWarningLamp 3040;
BA_ "SigType" SG_ 2566739454 FlashAmberWarningLamp 4;
BA_ "SPN" SG_ 2566739454 MalfunctionIndicatorLampStatus 1213;
BA_ "SigType" SG_ 2566739454 MalfunctionIndicatorLampStatus 4;
BA_ "SPN" SG_ 2566739454 AmberWarningLampStatus 624;
BA_ "SigType" SG_ 2566739454 AmberWarningLampStatus 4;
BA_ "SPN" SG_ 2566739454 RedStopLampStatus 623;
BA_ "SigType" SG_ 2566739454 RedStopLampStatus 4;
BA_ "SPN" SG_ 2566739454 ProtectLampStatus 987;
BA_ "SigType" SG_ 2566739454 ProtectLampStatus 4;
VAL_ 2564095742 SecurityEntityType 3 "Data is Certificate" 2 "Data is Session Key" 1 "Data is Long Key" 0 "Data is Long Seed" ;
VAL_ 2566742270 DM40_01FMI 31 "Not available" 19 "Received network data in error" 18 "Below normal (moderately severe)" 17 "Below normal (least severe)" 16 "Above normal (moderately severe)" 15 "Above normal (least severe)" 14 "Special intstructions" 13 "Out of calibration" 12 "Bad intelligent device" 11 "Root cause not known" 10 "Abnormal rate of change" 9 "Abnormal update rate" 8 "Abnormal frequency" 7 "Mechanical system not responding" 6 "Current above normal" 5 "Current below normal" 4 "Voltage below normal" 3 "Voltage above normal" 2 "Data erratic" 1 "Below normal (most severe)" 0 "Above normal (most severe)" ;
VAL_ 2560687870 PMNTEDeficiencyAreaStatus 3 "NotAvailable" 2 "Reserved" 1 "InsideControlArea" 0 "OutsideControlArea" ;
VAL_ 2560687870 MnfcPMNTECarveOutAreaStatus 3 "NotAvailable" 2 "Reserved" 1 "InsideControlArea" 0 "OutsideControlArea" ;
VAL_ 2560687870 PMNTEControlAreaStatus 3 "NotAvailable" 2 "Reserved" 1 "InsideControlArea" 0 "OutsideControlArea" ;
VAL_ 2560687870 NOxNTEDeficiencyAreaStatus 3 "NotAvailable" 2 "Reserved" 1 "InsideControlArea" 0 "OutsideControlArea" ;
VAL_ 2560687870 MnfcNOxNTECarveOutAreaStatus 3 "NotAvailable" 2 "Reserved" 1 "InsideControlArea" 0 "OutsideControlArea" ;
VAL_ 2560687870 NOxNTEControlAreaStatus 3 "NotAvailable" 2 "Reserved" 1 "InsideControlArea" 0 "OutsideControlArea" ;
VAL_ 2560884478 DTCWarnLampSupportStatus 3 "Unavailable" 2 "Reserved" 1 "LampOn" 0 "LampOff" ;
VAL_ 2560884478 DTCWarnLampSupportFlash 3 "Unavailable" 2 "Reserved" 1 "FastFlash" 0 "SlowFlash" ;
VAL_ 2560884478 DTCStopLampSupportStatus 3 "Unavailable" 2 "Reserved" 1 "LampOn" 0 "LampOff" ;
VAL_ 2560884478 DTCStopLampSupportFlash 3 "Unavailable" 2 "Reserved" 1 "FastFlash" 0 "SlowFlash" ;
VAL_ 2560884478 DTCProtectLampSupportStatus 3 "Unavailable" 2 "Reserved" 1 "LampOn" 0 "LampOff" ;
VAL_ 2560884478 DTCProtectLampSupportFlash 3 "Unavailable" 2 "Reserved" 1 "FastFlash" 0 "SlowFlash" ;
VAL_ 2560884478 DTCMilSupportStatus 3 "Unavailable" 2 "ShortMI" 1 "LampOn" 0 "LampOff" ;
VAL_ 2560884478 DTCMilSupportFlash 3 "Unavailable" 2 "Class_C_DTC" 1 "FastFlash" 0 "SlowFlash" ;
VAL_ 2560950014 DM30_01FMI 31 "Not available" 19 "Received network data in error" 18 "Below normal (moderately severe)" 17 "Below normal (least severe)" 16 "Above normal (moderately severe)" 15 "Above normal (least severe)" 14 "Special intstructions" 13 "Out of calibration" 12 "Bad intelligent device" 11 "Root cause not known" 10 "Abnormal rate of change" 9 "Abnormal update rate" 8 "Abnormal frequency" 7 "Mechanical system not responding" 6 "Current above normal" 5 "Current below normal" 4 "Voltage below normal" 3 "Voltage above normal" 2 "Data erratic" 1 "Below normal (most severe)" 0 "Above normal (most severe)" ;
VAL_ 2566836478 TestIdentifier 250 "Last Measured Scaled Results" 249 "Command Standard Test" 247 "All scaled test results" ;
VAL_ 2565078782 TestIdentifier 247 "All scaled test results" 249 "Command Standard Test" 250 "Last Measured Scaled Results" 245 "Return rationality fault SP data value" 246 "Return all scaled test results for all SPNs" ;
VAL_ 2565078782 DM07_01FMI 31 "Not available" 19 "Received network data in error" 18 "Below normal (moderately severe)" 17 "Below normal (least severe)" 16 "Above normal (moderately severe)" 15 "Above normal (least severe)" 14 "Special intstructions" 13 "Out of calibration" 12 "Bad intelligent device" 11 "Root cause not known" 10 "Abnormal rate of change" 9 "Abnormal update rate" 8 "Abnormal frequency" 7 "Mechanical system not responding" 6 "Current above normal" 5 "Current below normal" 4 "Voltage below normal" 3 "Voltage above normal" 2 "Data erratic" 1 "Below normal (most severe)" 0 "Above normal (most severe)" ;
VAL_ 2566836222 FlashRedStopLamp 3 "Unavailable / Do Not Flash" 2 "Reserved" 1 "Fast Flash" 0 "Slow Flash" ;
VAL_ 2566836222 FlashProtectLamp 3 "Unavailable / Do Not Flash" 2 "Reserved" 1 "Fast Flash" 0 "Slow Flash" ;
VAL_ 2566836222 FlashMalfuncIndicatorLamp 3 "Unavailable / Do Not Flash" 2 "Reserved" 1 "Fast Flash" 0 "Slow Flash" ;
VAL_ 2566836222 FlashAmberWarningLamp 3 "Unavailable / Do Not Flash" 2 "Reserved" 1 "Fast Flash" 0 "Slow Flash" ;
VAL_ 2566836222 MalfunctionIndicatorLampStatus 3 "Not available" 2 "Reserved" 1 "Lamp on" 0 "Lamp off" ;
VAL_ 2566836222 RedStopLampStatus 3 "Not available" 2 "Reserved" 1 "Lamp on" 0 "Lamp off" ;
VAL_ 2566836222 AmberWarningLampStatus 3 "Not available" 2 "Reserved" 1 "Lamp on" 0 "Lamp off" ;
VAL_ 2566836222 ProtectLampStatus 3 "Not available" 2 "Reserved" 1 "Lamp on" 0 "Lamp off" ;
VAL_ 2566835966 MisfireMonitoringSupport 3 "Not available" 2 "Reserved" 1 "test supported" 0 "test not supported" ;
VAL_ 2566835966 OBDCompliance 0 "Reserved for assignment by SAE" 1 "OBD II (California, ARB)" 2 "OBD (Federal, EPA)" 3 "OBD and OBD II" 4 "OBD I" 5 "Not intended to meet OBD II req." 6 "EOBD" 7 "EOBD and OBD II" 8 "EOBD and OBD" 9 "EOBD, OBD and OBD II" 10 "JOBD" 11 "JOBD and OBD II" 12 "JOBD and EOBD" 13 "JOBD, EOBD and OBD II" 14 "Heavy Duty Vehicles (EURO IV) B1" 15 "Heavy Duty Vehicles (EURO V) B2" 16 "Heavy Duty Vehicles (EURO EEC) C" 17 "EMD" 18 "EMD+" 19 "HD OBD P" 20 "HD OBD" 21 "WWH OBD" 22 "OBD II (California, ARB 07/08)" 23 "HD EOBD" 25 "OBD-M (SI-SD/I)" 26 "EURO VI" 27 "HD-ZEP" 28 "OBDBr-1" 29 "OBDBr-2" 30 "KOBD" 31 "IOBD I" 32 "IOBD II" 33 "HD EOBD-VI" 34 "OBD, OBD II, HD OBD" 35 "OBD, OBD II, HD OBD P" 41 "CN-OBD-6" 42 "OBDBr-D" 43 "CN-OBD-VI" 44 "IOBD-I-BS6" 45 "IOBD-II-BS6" 46 "IHDOBD-BSVI" 47 "OBDBr-P8" 48 "HD-JOBD-II" 49 "HD-KOBD-II" 50 "CN-HDOBD-IV" ;
VAL_ 2566835966 SecondAirSystemMonStatus 1 "TestNotComplete" 0 "TestComplete" ;
VAL_ 2566835966 EvaporativeSystemMonStatus 1 "TestNotComplete" 0 "TestComplete" ;
VAL_ 2566835966 ACSystemRefrigerantMonStatus 1 "TestNotComplete" 0 "TestComplete" ;
VAL_ 2566835966 OxygenSensorHeaterMonStatus 1 "TestNotComplete" 0 "TestComplete" ;
VAL_ 2566835966 OxygenSensorMonStatus 1 "test not complete" 0 "test complete" ;
VAL_ 2566835966 EGRSystemMonitoringStatus 1 "TestNotComplete" 0 "TestComplete" ;
VAL_ 2566835966 CatalystMonStatus 0 "TestComplete" 1 "TestNotComplete" ;
VAL_ 2566835966 ColdStartAidSystemMonStatus 1 "TestNotComplete" 0 "TestComplete" ;
VAL_ 2566835966 HeatedCatalystMonStatus 1 "TestNotComplete" 0 "TestComplete" ;
VAL_ 2566835966 CatalystMonSupp 1 "TestSupported" 0 "TestNotSupported" ;
VAL_ 2566835966 ColdStartAidSystemMonSupp 1 "TestSupported" 0 "TestNotSupported" ;
VAL_ 2566835966 HeatedCatalystMonSupp 1 "TestSupported" 0 "TestNotSupported" ;
VAL_ 2566835966 EvaporativeSystemMonSupp 1 "TestSupported" 0 "TestNotSupported" ;
VAL_ 2566835966 SecondAirSystemMonSupp 1 "TestSupported" 0 "TestNotSupported" ;
VAL_ 2566835966 ACSystemRefrigerantMonSupp 1 "TestSupported" 0 "TestNotSupported" ;
VAL_ 2566835966 OxygenSensorMonSupp 1 "TestSupported" 0 "TestNotSupported" ;
VAL_ 2566835966 OxygenSensorHeaterMonSupp 1 "TestSupported" 0 "TestNotSupported" ;
VAL_ 2566835966 EGRSystemMonitoringSupp 1 "TestSupported" 0 "TestNotSupported" ;
VAL_ 2566835966 MisfireMonitoringStatus 1 "test not complete" 0 "test complete" ;
VAL_ 2566835966 ComprehensiveCompMonStatus 1 "test not complete" 0 "test complete" ;
VAL_ 2566835966 FuelSystemMonitoringStatus 1 "test not complete" 0 "test complete" ;
VAL_ 2566835966 ComprehensiveComponentMonSupp 3 "Not available" 2 "Reserved" 1 "test supported" 0 "test not supported" ;
VAL_ 2566835966 FuelSystemMonitoringSupport 1 "test supported" 0 "test not supported" ;
VAL_ 2566835710 EngTorqueMode 15 "Not available" 11 "Remote accelerator" 10 "Braking system" 9 "High speed governor" 8 "Torque limiting" 7 "ABS control" 6 "Transmission control" 5 "ASR control" 4 "Road speed governor" 3 "PTO governor" 2 "Cruise control" 1 "Accelerator pedal/operator selec" 0 "Low idle governor/no request (de" ;
VAL_ 2566764286 SPNSupportTypeSTR3 1 "SupportedInScaledTestResults" 0 "NotSupportedInScaledTestResults" ;
VAL_ 2566764286 SPNSupportTypeSTR2 1 "SupportedInScaledTestResults" 0 "NotSupportedInScaledTestResults" ;
VAL_ 2566764286 SPNSupportTypeEFF3 1 "SupportedInExFreezeFrame" 0 "NotSupportedInExFreezeFrame" ;
VAL_ 2566764286 SPNSupportTypeEFF2 1 "SupportedInExFreezeFrame" 0 "NotSupportedInExFreezeFrame" ;
VAL_ 2566764286 SPNSupportTypeDS3 1 "SupportedInDataStream" 0 "NotSupportedInDataStream" ;
VAL_ 2566764286 SPNSupportTypeDS2 1 "SupportedInDataStream" 0 "NotSupportedInDataStream" ;
VAL_ 2566764286 SPNSupportTypeSTR1 1 "SupportedInScaledTestResults" 0 "NotSupportedInScaledTestResults" ;
VAL_ 2566764286 SPNSupportTypeDS1 1 "SupportedInDataStream" 0 "NotSupportedInDataStream" ;
VAL_ 2566764286 SPNSupportTypeEFF1 1 "SupportedInExFreezeFrame" 0 "NotSupportedInExFreezeFrame" ;
VAL_ 2566764030 FlashRedStopLamp 3 "Unavailable / Do Not Flash" 2 "Reserved" 1 "Fast Flash" 0 "Slow Flash" ;
VAL_ 2566764030 FlashProtectLamp 3 "Unavailable / Do Not Flash" 2 "Reserved" 1 "Fast Flash" 0 "Slow Flash" ;
VAL_ 2566764030 FlashMalfuncIndicatorLamp 3 "Unavailable / Do Not Flash" 2 "Reserved" 1 "Fast Flash" 0 "Slow Flash" ;
VAL_ 2566764030 FlashAmberWarningLamp 3 "Unavailable / Do Not Flash" 2 "Reserved" 1 "Fast Flash" 0 "Slow Flash" ;
VAL_ 2566764030 MalfunctionIndicatorLampStatus 3 "Not available" 2 "Reserved" 1 "Lamp on" 0 "Lamp off" ;
VAL_ 2566764030 RedStopLampStatus 3 "Not available" 2 "Reserved" 1 "Lamp on" 0 "Lamp off" ;
VAL_ 2566764030 AmberWarningLampStatus 3 "Not available" 2 "Reserved" 1 "Lamp on" 0 "Lamp off" ;
VAL_ 2566764030 ProtectLampStatus 3 "Not available" 2 "Reserved" 1 "Lamp on" 0 "Lamp off" ;
VAL_ 2562981630 DM22_01FMI 31 "Not available" 19 "Received network data in error" 18 "Below normal (moderately severe)" 17 "Below normal (least severe)" 16 "Above normal (moderately severe)" 15 "Above normal (least severe)" 14 "Special intstructions" 13 "Out of calibration" 12 "Bad intelligent device" 11 "Root cause not known" 10 "Abnormal rate of change" 9 "Abnormal update rate" 8 "Abnormal frequency" 7 "Mechanical system not responding" 6 "Current above normal" 5 "Current below normal" 4 "Voltage below normal" 3 "Voltage above normal" 2 "Data erratic" 1 "Below normal (most severe)" 0 "Above normal (most severe)" ;
VAL_ 2566835198 MalfunctionIndicatorLampStatus 3 "Not available" 2 "Reserved" 1 "Lamp on" 0 "Lamp off" ;
VAL_ 2566835198 RedStopLampStatus 3 "Not available" 2 "Reserved" 1 "Lamp on" 0 "Lamp off" ;
VAL_ 2566835198 AmberWarningLampStatus 3 "Not available" 2 "Reserved" 1 "Lamp on" 0 "Lamp off" ;
VAL_ 2566835198 ProtectLampStatus 3 "Not available" 2 "Reserved" 1 "Lamp on" 0 "Lamp off" ;
VAL_ 2566835198 FlashRedStopLamp 3 "Unavailable / Do Not Flash" 2 "Reserved" 1 "Fast Flash" 0 "Slow Flash" ;
VAL_ 2566835198 FlashProtectLamp 3 "Unavailable / Do Not Flash" 2 "Reserved" 1 "Fast Flash" 0 "Slow Flash" ;
VAL_ 2566835198 FlashMalfuncIndicatorLamp 3 "Unavailable / Do Not Flash" 2 "Reserved" 1 "Fast Flash" 0 "Slow Flash" ;
VAL_ 2566835198 FlashAmberWarningLamp 3 "Unavailable / Do Not Flash" 2 "Reserved" 1 "Fast Flash" 0 "Slow Flash" ;
VAL_ 2564357886 Seed 255 "NoFurtherKeyRequiredOfTool" 1 "UseLongSeedOrKeyFromDataSecMsg" 0 "SeedCompleted_BeginSendingKey" ;
VAL_ 2564357886 EDCP_Extension 9 "DataInErrIndAndDataInSeedIsTime" 6 "DataInErrorIndicator" 3 "ConcatenateDataAsLowerEDCParam" 2 "ConcatenateDataAsHigherEDCParam" 0 "Completed" 255 "NoErrIndicator/EDCParamAvailable" ;
VAL_ 2564357886 ErrorIndicator 16777215 "NoErrorIndicatorAvailable" 65540 "TransprtNotComplWithinTimeAllowd" 65539 "TransportNotInitWithinTimeAllowd" 65538 "NoResponseInTheTimeAllowed" 65537 "ModuleExceedingNumberOfRetries" 65536 "AbortFromExtToNormalSoftwareProc" 4103 "VehicleNotInParkOrNotStationary" 4102 "EngineRunning" 4101 "NotInEngineeringOrDevelopmentMode" 4100 "NotInDiagnosticMode" 4099 "InvalidKey" 4098 "InvalidUserLevel" 4097 "InvalidPassword" 4096 "SecurityErrorGeneral" 266 "NameDoesNotConformToExpectdValue" 265 "DataDoesNotConformToValueRanges" 264 "AddrForBootLoadExeInvalidBoundary" 263 "AddrForBootLoadExeOutsideExeMem" 262 "OpReqExeTransfAndEraseOfProgMem" 261 "OpRequiresPriorEraseOfProgramMem" 260 "OpRequiresPriorEraseOfDataMem" 259 "ReqMemoryExceededAvailableMemory" 258 "LengthNotValidForMemStructAndOp" 257 "AddressNotOnValidBoundary" 256 "AddressingOrDataGeneralError" 36 "InternalFailurePreventingReq" 35 "PROMDidNotVerifyOnWrite" 34 "FLASHDidNotVerifyOnWrite" 33 "RAMDidNotVerifyOnWrite" 32 "EDCParaNotCorrectForDataStream" 31 "ProcessUnspecReqFromThisAddress" 23 "ProcessingEDCPGenerationReq" 22 "ProcessingBootLoadReq" 19 "ProcessingStatusReq" 18 "ProcessingWriteReq" 17 "ProcessingReadReq" 16 "ProcessingEraseReq" 2 "ProcessingForSomeoneElse" 1 "ErrorNotIdentified" 0 "NoError" ;
VAL_ 2564357886 Status 7 "Reserved" 6 "Reserved" 5 "OperationFailed" 4 "OperationCompleted" 3 "Reserved" 2 "Reserved" 1 "Busy" 0 "Proceed" ;
VAL_ 2564423422 KeyOrUserLevel 65535 "NoKeyAvailable" 0 "UseLongSeedOrKey" ;
VAL_ 2564423422 PointerExtension 0 "SPN_SPACE" ;
VAL_ 2564423422 Command 7 "EDCP_Generation" 6 "BootLoad" 5 "OperationFailed" 4 "OperationCompleted" 3 "StatusRequest" 2 "Write" 1 "Read" 0 "Erase" ;
VAL_ 2564423422 PointerType 1 "DirectedSpatialAddressing" 0 "DirectMemoryAddressing" ;
VAL_ 2564816638 HoldSignal 15 "Not available" 1 "Devices whose broadcast state ha" 0 "All devices" ;
VAL_ 2564816638 J1939Network3 3 "Don't care" 2 "Reserved" 1 "Start broadcast" 0 "Stop broadcast" ;
VAL_ 2564816638 J1939Network2 3 "Don't care" 2 "Reserved" 1 "Start broadcast" 0 "Stop broadcast" ;
VAL_ 2564816638 ISO9141 3 "Don't care" 2 "Reserved" 1 "Start broadcast" 0 "Stop broadcast" ;
VAL_ 2564816638 SAE_J1850 3 "Don't care" 2 "Reserved" 1 "Start broadcast" 0 "Stop broadcast" ;
VAL_ 2564816638 ManufacturerSpecificPort 3 "Don't care" 2 "Reserved" 1 "Start broadcast" 0 "Stop broadcast" ;
VAL_ 2564816638 CurrentDataLink 3 "Don't care" 2 "Reserved" 1 "Start broadcast" 0 "Stop broadcast" ;
VAL_ 2564816638 SAE_J1587 3 "Don't care" 2 "Reserved" 1 "Start broadcast" 0 "Stop broadcast" ;
VAL_ 2564816638 SAE_J1922 3 "Don't care" 2 "Reserved" 1 "Start broadcast" 0 "Stop broadcast" ;
VAL_ 2564816638 J1939Network1 3 "Don't care" 2 "Reserved" 1 "Start broadcast" 0 "Stop broadcast" ;
VAL_ 2564816638 SuspendSignal 15 "NotAvailable" 14 "ResumingNormalBroadcastPattern" 3 "TemporarySuspensionOfSomeMessages" 2 "TemporarySuspensionOfAllBroadcasts" 1 "IndefiniteSuspensionOfSomeMessages" 0 "IndefiniteSuspensionOfAllBroadcasts" ;
VAL_ 2566837502 FlashRedStopLamp 3 "Unavailable / Do Not Flash" 2 "Reserved" 1 "Fast Flash" 0 "Slow Flash" ;
VAL_ 2566837502 FlashProtectLamp 3 "Unavailable / Do Not Flash" 2 "Reserved" 1 "Fast Flash" 0 "Slow Flash" ;
VAL_ 2566837502 MalfunctionIndicatorLampStatus 3 "Not available" 2 "Reserved" 1 "Lamp on" 0 "Lamp off" ;
VAL_ 2566837502 RedStopLampStatus 3 "Not available" 2 "Reserved" 1 "Lamp on" 0 "Lamp off" ;
VAL_ 2566837502 AmberWarningLampStatus 3 "Not available" 2 "Reserved" 1 "Lamp on" 0 "Lamp off" ;
VAL_ 2566837502 ProtectLampStatus 3 "Not available" 2 "Reserved" 1 "Lamp on" 0 "Lamp off" ;
VAL_ 2566837502 FlashMalfuncIndicatorLamp 3 "Unavailable / Do Not Flash" 2 "Reserved" 1 "Fast Flash" 0 "Slow Flash" ;
VAL_ 2566837502 FlashAmberWarningLamp 3 "Unavailable / Do Not Flash" 2 "Reserved" 1 "Fast Flash" 0 "Slow Flash" ;
VAL_ 2566834942 FlashRedStopLamp 3 "Unavailable / Do Not Flash" 2 "Reserved" 1 "Fast Flash" 0 "Slow Flash" ;
VAL_ 2566834942 FlashProtectLamp 3 "Unavailable / Do Not Flash" 2 "Reserved" 1 "Fast Flash" 0 "Slow Flash" ;
VAL_ 2566834942 FlashMalfuncIndicatorLamp 3 "Unavailable / Do Not Flash" 2 "Reserved" 1 "Fast Flash" 0 "Slow Flash" ;
VAL_ 2566834942 FlashAmberWarningLamp 3 "Unavailable / Do Not Flash" 2 "Reserved" 1 "Fast Flash" 0 "Slow Flash" ;
VAL_ 2566834942 MalfunctionIndicatorLampStatus 3 "Not available" 2 "Reserved" 1 "Lamp on" 0 "Lamp off" ;
VAL_ 2566834942 AmberWarningLampStatus 3 "Not available" 2 "Reserved" 1 "Lamp on" 0 "Lamp off" ;
VAL_ 2566834942 RedStopLampStatus 3 "Not available" 2 "Reserved" 1 "Lamp on" 0 "Lamp off" ;
VAL_ 2566834942 ProtectLampStatus 3 "Not available" 2 "Reserved" 1 "Lamp on" 0 "Lamp off" ;
VAL_ 2566739198 FlashRedStopLamp 3 "Unavailable / Do Not Flash" 2 "Reserved" 1 "Fast Flash" 0 "Slow Flash" ;
VAL_ 2566739198 FlashProtectLamp 3 "Unavailable / Do Not Flash" 2 "Reserved" 1 "Fast Flash" 0 "Slow Flash" ;
VAL_ 2566739198 FlashMalfuncIndicatorLamp 3 "Unavailable / Do Not Flash" 2 "Reserved" 1 "Fast Flash" 0 "Slow Flash" ;
VAL_ 2566739198 FlashAmberWarningLamp 3 "Unavailable / Do Not Flash" 2 "Reserved" 1 "Fast Flash" 0 "Slow Flash" ;
VAL_ 2566739198 MalfunctionIndicatorLampStatus 3 "Not available" 2 "Reserved" 1 "Lamp on" 0 "Lamp off" ;
VAL_ 2566739198 AmberWarningLampStatus 3 "Not available" 2 "Reserved" 1 "Lamp on" 0 "Lamp off" ;
VAL_ 2566739198 RedStopLampStatus 3 "Not available" 2 "Reserved" 1 "Lamp on" 0 "Lamp off" ;
VAL_ 2566739198 ProtectLampStatus 3 "Not available" 2 "Reserved" 1 "Lamp on" 0 "Lamp off" ;
VAL_ 2566739454 FlashRedStopLamp 3 "Unavailable / Do Not Flash" 2 "Reserved" 1 "Fast Flash" 0 "Slow Flash" ;
VAL_ 2566739454 FlashProtectLamp 3 "Unavailable / Do Not Flash" 2 "Reserved" 1 "Fast Flash" 0 "Slow Flash" ;
VAL_ 2566739454 FlashMalfuncIndicatorLamp 3 "Unavailable / Do Not Flash" 2 "Reserved" 1 "Fast Flash" 0 "Slow Flash" ;
VAL_ 2566739454 FlashAmberWarningLamp 3 "Unavailable / Do Not Flash" 2 "Reserved" 1 "Fast Flash" 0 "Slow Flash" ;
VAL_ 2566739454 MalfunctionIndicatorLampStatus 3 "Not available" 2 "Reserved" 1 "Lamp on" 0 "Lamp off" ;
VAL_ 2566739454 AmberWarningLampStatus 3 "Not available" 2 "Reserved" 1 "Lamp on" 0 "Lamp off" ;
VAL_ 2566739454 RedStopLampStatus 3 "Not available" 2 "Reserved" 1 "Lamp on" 0 "Lamp off" ;
VAL_ 2566739454 ProtectLampStatus 3 "Not available" 2 "Reserved" 1 "Lamp on" 0 "Lamp off" ;
